[part 10 of 12: packages /Interfaces to /ComponentTypes]
AUTOSAR XML (schema 4-3-0)
package /Interfaces
  1007 x sender receiver interface:
    IF_AB_Deaktivierung_HV
      data DE_AB_Deaktivierung_HV: type=uint8
    IF_Anzeige_SOC
      data DE_Anzeige_SOC: type=uint16
    IF_BJB_10_BZ
      data DE_BJB_10_BZ: type=uint8
    IF_BJB_10_CRC
      data DE_BJB_10_CRC: type=uint8
    IF_BJB_11_BZ
      data DE_BJB_11_BZ: type=uint8
    IF_BJB_11_CRC
      data DE_BJB_11_CRC: type=uint8
    IF_BJB_12_BZ
      data DE_BJB_12_BZ: type=uint8
    IF_BJB_12_CRC
      data DE_BJB_12_CRC: type=uint8
    IF_BJB_13_BZ
      data DE_BJB_13_BZ: type=uint8
    IF_BJB_13_CRC
      data DE_BJB_13_CRC: type=uint8
    IF_BJB_CALID_Index_01
      data DE_BJB_CALID_Index_01: type=uint8
    IF_BJB_CALID_Index_02
      data DE_BJB_CALID_Index_02: type=uint8
    IF_BJB_CALID_Index_03
      data DE_BJB_CALID_Index_03: type=uint8
    IF_BJB_CALID_Index_04
      data DE_BJB_CALID_Index_04: type=uint8
    IF_BJB_CALID_Index_05
      data DE_BJB_CALID_Index_05: type=uint8
    IF_BJB_CALID_Index_06
      data DE_BJB_CALID_Index_06: type=uint8
    IF_BJB_CALID_Index_07
      data DE_BJB_CALID_Index_07: type=uint8
    IF_BJB_CALID_Index_08
      data DE_BJB_CALID_Index_08: type=uint8
    IF_BJB_CALID_Index_09
      data DE_BJB_CALID_Index_09: type=uint8
    IF_BJB_CALID_Index_10
      data DE_BJB_CALID_Index_10: type=uint8
    IF_BJB_CALID_Index_11
      data DE_BJB_CALID_Index_11: type=uint8
    IF_BJB_CALID_Index_12
      data DE_BJB_CALID_Index_12: type=uint8
    IF_BJB_CALID_Index_13
      data DE_BJB_CALID_Index_13: type=uint8
    IF_BJB_CALID_Index_14
      data DE_BJB_CALID_Index_14: type=uint8
    IF_BJB_CALID_Index_15
      data DE_BJB_CALID_Index_15: type=uint8
    IF_BJB_CALID_Index_16
      data DE_BJB_CALID_Index_16: type=uint8
    IF_BJB_CVN_Byte_1
      data DE_BJB_CVN_Byte_1: type=uint8
    IF_BJB_CVN_Byte_2
      data DE_BJB_CVN_Byte_2: type=uint8
    IF_BJB_CVN_Byte_3
      data DE_BJB_CVN_Byte_3: type=uint8
    IF_BJB_CVN_Byte_4
      data DE_BJB_CVN_Byte_4: type=uint8
    IF_BJB_CVN_VLD
      data DE_BJB_CVN_VLD: type=boolean
    IF_BJB_ErrMem_State
      data DE_BJB_ErrMem_State: type=uint8
    IF_BJB_Lebensdauer_Trennelemente
      data DE_BJB_Lebensdauer_Trennelemente: type=uint32
    IF_BJB_Sperrung_Ueberspannung
      data DE_BJB_Sperrung_Ueberspannung: type=uint8
    IF_BJB_Sperrung_Uebertemperatur
      data DE_BJB_Sperrung_Uebertemperatur: type=uint8
    IF_BJB_Sperrung_Unterspannung
      data DE_BJB_Sperrung_Unterspannung: type=uint8
    IF_BJB_Status_HV_Spannungssensorik
      data DE_BJB_Status_HV_Spannungssensorik: type=boolean
    IF_BJB_Status_Trennelemente
      data DE_BJB_Status_Trennelemente: type=uint8
    IF_BJB_Ueberspannungszaehler_CMC01
      data DE_BJB_Ueberspannungszaehler_CMC01: type=uint16
    IF_BJB_Ueberspannungszaehler_CMC02
      data DE_BJB_Ueberspannungszaehler_CMC02: type=uint16
    IF_BJB_Ueberspannungszaehler_CMC03
      data DE_BJB_Ueberspannungszaehler_CMC03: type=uint16
    IF_BJB_Ueberspannungszaehler_CMC04
      data DE_BJB_Ueberspannungszaehler_CMC04: type=uint16
    IF_BJB_Uebertemperaturzaehler_CMC01
      data DE_BJB_Uebertemperaturzaehler_CMC01: type=uint16
    IF_BJB_Uebertemperaturzaehler_CMC02
      data DE_BJB_Uebertemperaturzaehler_CMC02: type=uint16
    IF_BJB_Uebertemperaturzaehler_CMC03
      data DE_BJB_Uebertemperaturzaehler_CMC03: type=uint16
    IF_BJB_Uebertemperaturzaehler_CMC04
      data DE_BJB_Uebertemperaturzaehler_CMC04: type=uint16
    IF_BJB_Unterspannungszaehler_CMC01
      data DE_BJB_Unterspannungszaehler_CMC01: type=uint16
    IF_BJB_Unterspannungszaehler_CMC02
      data DE_BJB_Unterspannungszaehler_CMC02: type=uint16
    IF_BJB_Unterspannungszaehler_CMC03
      data DE_BJB_Unterspannungszaehler_CMC03: type=uint16
    IF_BJB_Unterspannungszaehler_CMC04
      data DE_BJB_Unterspannungszaehler_CMC04: type=uint16
    IF_BMC_Abschaltankuendigung
      data DE_BMC_Abschaltankuendigung: type=uint16
    IF_BMC_AC_Laden
      data DE_BMC_AC_Laden: type=uint8
    IF_BMC_Bank_Notlauf_erlaubt
      data DE_BMC_Bank_Notlauf_erlaubt: type=boolean
    IF_BMC_Bank_parallel_erlaubt
      data DE_BMC_Bank_parallel_erlaubt: type=boolean
    IF_BMC_Bank_seriell_erlaubt
      data DE_BMC_Bank_seriell_erlaubt: type=boolean
    IF_BMC_Bankstatus
      data DE_BMC_Bankstatus: type=uint8
    IF_BMC_Bidi_Energie_Absolut
      data DE_BMC_Bidi_Energie_Absolut: type=uint16
    IF_BMC_Bidi_Freigabe
      data DE_BMC_Bidi_Freigabe: type=uint8
    IF_BMC_Bidi_GenutzteEnergie
      data DE_BMC_Bidi_GenutzteEnergie: type=uint16
    IF_BMC_Bidi_Max_SoC
      data DE_BMC_Bidi_Max_SoC: type=uint8
    IF_BMC_Bidi_Min_SoC
      data DE_BMC_Bidi_Min_SoC: type=uint8
    IF_BMC_Bidi_Veto_Energie
      data DE_BMC_Bidi_Veto_Energie: type=boolean
    IF_BMC_Bidi_Veto_Temp
      data DE_BMC_Bidi_Veto_Temp: type=boolean
    IF_BMC_CMC_Temperatur_001
      data DE_BMC_CMC_Temperatur_001: type=uint8
    IF_BMC_CMC_Temperatur_002
      data DE_BMC_CMC_Temperatur_002: type=uint8
    IF_BMC_CMC_Temperatur_003
      data DE_BMC_CMC_Temperatur_003: type=uint8
    IF_BMC_CMC_Temperatur_004
      data DE_BMC_CMC_Temperatur_004: type=uint8
    IF_BMC_CMC_Temperatur_005
      data DE_BMC_CMC_Temperatur_005: type=uint8
    IF_BMC_CMC_Temperatur_006
      data DE_BMC_CMC_Temperatur_006: type=uint8
    IF_BMC_CMC_Temperatur_007
      data DE_BMC_CMC_Temperatur_007: type=uint8
    IF_BMC_CMC_Temperatur_008
      data DE_BMC_CMC_Temperatur_008: type=uint8
    IF_BMC_CMC_Temperatur_009
      data DE_BMC_CMC_Temperatur_009: type=uint8
    IF_BMC_CMC_Temperatur_010
      data DE_BMC_CMC_Temperatur_010: type=uint8
    IF_BMC_CMC_Temperatur_011
      data DE_BMC_CMC_Temperatur_011: type=uint8
    IF_BMC_CMC_Temperatur_012
      data DE_BMC_CMC_Temperatur_012: type=uint8
    IF_BMC_CMC_Temperatur_013
      data DE_BMC_CMC_Temperatur_013: type=uint8
    IF_BMC_CMC_Temperatur_014
      data DE_BMC_CMC_Temperatur_014: type=uint8
    IF_BMC_CMC_Temperatur_015
      data DE_BMC_CMC_Temperatur_015: type=uint8
    IF_BMC_CMC_Temperatur_016
      data DE_BMC_CMC_Temperatur_016: type=uint8
    IF_BMC_CMC_Temperatur_017
      data DE_BMC_CMC_Temperatur_017: type=uint8
    IF_BMC_CMC_Temperatur_018
      data DE_BMC_CMC_Temperatur_018: type=uint8
    IF_BMC_CMC_Temperatur_019
      data DE_BMC_CMC_Temperatur_019: type=uint8
    IF_BMC_CMC_Temperatur_01_Messzeit
      data DE_BMC_CMC_Temperatur_01_Messzeit: type=uint8
    IF_BMC_CMC_Temperatur_020
      data DE_BMC_CMC_Temperatur_020: type=uint8
    IF_BMC_CMC_Temperatur_021
      data DE_BMC_CMC_Temperatur_021: type=uint8
    IF_BMC_CMC_Temperatur_022
      data DE_BMC_CMC_Temperatur_022: type=uint8
    IF_BMC_CMC_Temperatur_023
      data DE_BMC_CMC_Temperatur_023: type=uint8
    IF_BMC_CMC_Temperatur_024
      data DE_BMC_CMC_Temperatur_024: type=uint8
    IF_BMC_CMC_Temperatur_025
      data DE_BMC_CMC_Temperatur_025: type=uint8
    IF_BMC_CMC_Temperatur_026
      data DE_BMC_CMC_Temperatur_026: type=uint8
    IF_BMC_CMC_Temperatur_027
      data DE_BMC_CMC_Temperatur_027: type=uint8
    IF_BMC_CMC_Temperatur_028
      data DE_BMC_CMC_Temperatur_028: type=uint8
    IF_BMC_CMC_Temperatur_029
      data DE_BMC_CMC_Temperatur_029: type=uint8
    IF_BMC_CMC_Temperatur_02_Messzeit
      data DE_BMC_CMC_Temperatur_02_Messzeit: type=uint8
    IF_BMC_CMC_Temperatur_030
      data DE_BMC_CMC_Temperatur_030: type=uint8
    IF_BMC_CMC_Temperatur_031
      data DE_BMC_CMC_Temperatur_031: type=uint8
    IF_BMC_CMC_Temperatur_032
      data DE_BMC_CMC_Temperatur_032: type=uint8
    IF_BMC_CMC_Temperatur_033
      data DE_BMC_CMC_Temperatur_033: type=uint8
    IF_BMC_CMC_Temperatur_034
      data DE_BMC_CMC_Temperatur_034: type=uint8
    IF_BMC_CMC_Temperatur_035
      data DE_BMC_CMC_Temperatur_035: type=uint8
    IF_BMC_CMC_Temperatur_036
      data DE_BMC_CMC_Temperatur_036: type=uint8
    IF_BMC_CMC_Temperatur_037
      data DE_BMC_CMC_Temperatur_037: type=uint8
    IF_BMC_CMC_Temperatur_038
      data DE_BMC_CMC_Temperatur_038: type=uint8
    IF_BMC_CMC_Temperatur_039
      data DE_BMC_CMC_Temperatur_039: type=uint8
    IF_BMC_CMC_Temperatur_03_Messzeit
      data DE_BMC_CMC_Temperatur_03_Messzeit: type=uint8
    IF_BMC_CMC_Temperatur_040
      data DE_BMC_CMC_Temperatur_040: type=uint8
    IF_BMC_CMC_Temperatur_041
      data DE_BMC_CMC_Temperatur_041: type=uint8
    IF_BMC_CMC_Temperatur_042
      data DE_BMC_CMC_Temperatur_042: type=uint8
    IF_BMC_CMC_Temperatur_043
      data DE_BMC_CMC_Temperatur_043: type=uint8
    IF_BMC_CMC_Temperatur_044
      data DE_BMC_CMC_Temperatur_044: type=uint8
    IF_BMC_CMC_Temperatur_045
      data DE_BMC_CMC_Temperatur_045: type=uint8
    IF_BMC_CMC_Temperatur_046
      data DE_BMC_CMC_Temperatur_046: type=uint8
    IF_BMC_CMC_Temperatur_047
      data DE_BMC_CMC_Temperatur_047: type=uint8
    IF_BMC_CMC_Temperatur_048
      data DE_BMC_CMC_Temperatur_048: type=uint8
    IF_BMC_CMC_Temperatur_049
      data DE_BMC_CMC_Temperatur_049: type=uint8
    IF_BMC_CMC_Temperatur_050
      data DE_BMC_CMC_Temperatur_050: type=uint8
    IF_BMC_CMC_Temperatur_051
      data DE_BMC_CMC_Temperatur_051: type=uint8
    IF_BMC_CMC_Temperatur_052
      data DE_BMC_CMC_Temperatur_052: type=uint8
    IF_BMC_CMC_Temperatur_053
      data DE_BMC_CMC_Temperatur_053: type=uint8
    IF_BMC_CMC_Temperatur_054
      data DE_BMC_CMC_Temperatur_054: type=uint8
    IF_BMC_CMC_Temperatur_055
      data DE_BMC_CMC_Temperatur_055: type=uint8
    IF_BMC_CMC_Temperatur_056
      data DE_BMC_CMC_Temperatur_056: type=uint8
    IF_BMC_CMC_Temperatur_057
      data DE_BMC_CMC_Temperatur_057: type=uint8
    IF_BMC_CMC_Temperatur_058
      data DE_BMC_CMC_Temperatur_058: type=uint8
    IF_BMC_CMC_Temperatur_059
      data DE_BMC_CMC_Temperatur_059: type=uint8
    IF_BMC_CMC_Temperatur_060
      data DE_BMC_CMC_Temperatur_060: type=uint8
    IF_BMC_CMC_Temperatur_061
      data DE_BMC_CMC_Temperatur_061: type=uint8
    IF_BMC_CMC_Temperatur_062
      data DE_BMC_CMC_Temperatur_062: type=uint8
    IF_BMC_CMC_Temperatur_063
      data DE_BMC_CMC_Temperatur_063: type=uint8
    IF_BMC_CMC_Temperatur_064
      data DE_BMC_CMC_Temperatur_064: type=uint8
    IF_BMC_CMC_Temperatur_065
      data DE_BMC_CMC_Temperatur_065: type=uint8
    IF_BMC_CMC_Temperatur_066
      data DE_BMC_CMC_Temperatur_066: type=uint8
    IF_BMC_CMC_Temperatur_067
      data DE_BMC_CMC_Temperatur_067: type=uint8
    IF_BMC_CMC_Temperatur_068
      data DE_BMC_CMC_Temperatur_068: type=uint8
    IF_BMC_CMC_Temperatur_069
      data DE_BMC_CMC_Temperatur_069: type=uint8
    IF_BMC_CMC_Temperatur_070
      data DE_BMC_CMC_Temperatur_070: type=uint8
    IF_BMC_CMC_Temperatur_071
      data DE_BMC_CMC_Temperatur_071: type=uint8
    IF_BMC_CMC_Temperatur_072
      data DE_BMC_CMC_Temperatur_072: type=uint8
    IF_BMC_CMC_Temperatur_073
      data DE_BMC_CMC_Temperatur_073: type=uint8
    IF_BMC_CMC_Temperatur_074
      data DE_BMC_CMC_Temperatur_074: type=uint8
    IF_BMC_CMC_Temperatur_075
      data DE_BMC_CMC_Temperatur_075: type=uint8
    IF_BMC_CMC_Temperatur_076
      data DE_BMC_CMC_Temperatur_076: type=uint8
    IF_BMC_CMC_Temperatur_077
      data DE_BMC_CMC_Temperatur_077: type=uint8
    IF_BMC_CMC_Temperatur_078
      data DE_BMC_CMC_Temperatur_078: type=uint8
    IF_BMC_CMC_Temperatur_079
      data DE_BMC_CMC_Temperatur_079: type=uint8
    IF_BMC_CMC_Temperatur_080
      data DE_BMC_CMC_Temperatur_080: type=uint8
    IF_BMC_CMC_Temperatur_081
      data DE_BMC_CMC_Temperatur_081: type=uint8
    IF_BMC_CMC_Temperatur_082
      data DE_BMC_CMC_Temperatur_082: type=uint8
    IF_BMC_CMC_Temperatur_083
      data DE_BMC_CMC_Temperatur_083: type=uint8
    IF_BMC_CMC_Temperatur_084
      data DE_BMC_CMC_Temperatur_084: type=uint8
    IF_BMC_CMC_Temperatur_085
      data DE_BMC_CMC_Temperatur_085: type=uint8
    IF_BMC_CMC_Temperatur_086
      data DE_BMC_CMC_Temperatur_086: type=uint8
    IF_BMC_CMC_Temperatur_087
      data DE_BMC_CMC_Temperatur_087: type=uint8
    IF_BMC_CMC_Temperatur_088
      data DE_BMC_CMC_Temperatur_088: type=uint8
    IF_BMC_CMC_Temperatur_089
      data DE_BMC_CMC_Temperatur_089: type=uint8
    IF_BMC_CMC_Temperatur_090
      data DE_BMC_CMC_Temperatur_090: type=uint8
    IF_BMC_CMC_Temperatur_091
      data DE_BMC_CMC_Temperatur_091: type=uint8
    IF_BMC_CMC_Temperatur_092
      data DE_BMC_CMC_Temperatur_092: type=uint8
    IF_BMC_CMC_Temperatur_093
      data DE_BMC_CMC_Temperatur_093: type=uint8
    IF_BMC_CMC_Temperatur_094
      data DE_BMC_CMC_Temperatur_094: type=uint8
    IF_BMC_CMC_Temperatur_095
      data DE_BMC_CMC_Temperatur_095: type=uint8
    IF_BMC_CMC_Temperatur_096
      data DE_BMC_CMC_Temperatur_096: type=uint8
    IF_BMC_CMC_Zellspannung_001
      data DE_BMC_CMC_Zellspannung_001: type=uint16
    IF_BMC_CMC_Zellspannung_002
      data DE_BMC_CMC_Zellspannung_002: type=uint16
    IF_BMC_CMC_Zellspannung_003
      data DE_BMC_CMC_Zellspannung_003: type=uint16
    IF_BMC_CMC_Zellspannung_004
      data DE_BMC_CMC_Zellspannung_004: type=uint16
    IF_BMC_CMC_Zellspannung_005
      data DE_BMC_CMC_Zellspannung_005: type=uint16
    IF_BMC_CMC_Zellspannung_006
      data DE_BMC_CMC_Zellspannung_006: type=uint16
    IF_BMC_CMC_Zellspannung_007
      data DE_BMC_CMC_Zellspannung_007: type=uint16
    IF_BMC_CMC_Zellspannung_008
      data DE_BMC_CMC_Zellspannung_008: type=uint16
    IF_BMC_CMC_Zellspannung_009
      data DE_BMC_CMC_Zellspannung_009: type=uint16
    IF_BMC_CMC_Zellspannung_010
      data DE_BMC_CMC_Zellspannung_010: type=uint16
    IF_BMC_CMC_Zellspannung_011
      data DE_BMC_CMC_Zellspannung_011: type=uint16
    IF_BMC_CMC_Zellspannung_012
      data DE_BMC_CMC_Zellspannung_012: type=uint16
    IF_BMC_CMC_Zellspannung_013
      data DE_BMC_CMC_Zellspannung_013: type=uint16
    IF_BMC_CMC_Zellspannung_014
      data DE_BMC_CMC_Zellspannung_014: type=uint16
    IF_BMC_CMC_Zellspannung_015
      data DE_BMC_CMC_Zellspannung_015: type=uint16
    IF_BMC_CMC_Zellspannung_016
      data DE_BMC_CMC_Zellspannung_016: type=uint16
    IF_BMC_CMC_Zellspannung_017
      data DE_BMC_CMC_Zellspannung_017: type=uint16
    IF_BMC_CMC_Zellspannung_018
      data DE_BMC_CMC_Zellspannung_018: type=uint16
    IF_BMC_CMC_Zellspannung_019
      data DE_BMC_CMC_Zellspannung_019: type=uint16
    IF_BMC_CMC_Zellspannung_01_Messzeit
      data DE_BMC_CMC_Zellspannung_01_Messzeit: type=uint8
    IF_BMC_CMC_Zellspannung_020
      data DE_BMC_CMC_Zellspannung_020: type=uint16
    IF_BMC_CMC_Zellspannung_021
      data DE_BMC_CMC_Zellspannung_021: type=uint16
    IF_BMC_CMC_Zellspannung_022
      data DE_BMC_CMC_Zellspannung_022: type=uint16
    IF_BMC_CMC_Zellspannung_023
      data DE_BMC_CMC_Zellspannung_023: type=uint16
    IF_BMC_CMC_Zellspannung_024
      data DE_BMC_CMC_Zellspannung_024: type=uint16
    IF_BMC_CMC_Zellspannung_025
      data DE_BMC_CMC_Zellspannung_025: type=uint16
    IF_BMC_CMC_Zellspannung_026
      data DE_BMC_CMC_Zellspannung_026: type=uint16
    IF_BMC_CMC_Zellspannung_027
      data DE_BMC_CMC_Zellspannung_027: type=uint16
    IF_BMC_CMC_Zellspannung_028
      data DE_BMC_CMC_Zellspannung_028: type=uint16
    IF_BMC_CMC_Zellspannung_029
      data DE_BMC_CMC_Zellspannung_029: type=uint16
    IF_BMC_CMC_Zellspannung_02_Messzeit
      data DE_BMC_CMC_Zellspannung_02_Messzeit: type=uint8
    IF_BMC_CMC_Zellspannung_030
      data DE_BMC_CMC_Zellspannung_030: type=uint16
    IF_BMC_CMC_Zellspannung_031
      data DE_BMC_CMC_Zellspannung_031: type=uint16
    IF_BMC_CMC_Zellspannung_032
      data DE_BMC_CMC_Zellspannung_032: type=uint16
    IF_BMC_CMC_Zellspannung_033
      data DE_BMC_CMC_Zellspannung_033: type=uint16
    IF_BMC_CMC_Zellspannung_034
      data DE_BMC_CMC_Zellspannung_034: type=uint16
    IF_BMC_CMC_Zellspannung_035
      data DE_BMC_CMC_Zellspannung_035: type=uint16
    IF_BMC_CMC_Zellspannung_036
      data DE_BMC_CMC_Zellspannung_036: type=uint16
    IF_BMC_CMC_Zellspannung_037
      data DE_BMC_CMC_Zellspannung_037: type=uint16
    IF_BMC_CMC_Zellspannung_038
      data DE_BMC_CMC_Zellspannung_038: type=uint16
    IF_BMC_CMC_Zellspannung_039
      data DE_BMC_CMC_Zellspannung_039: type=uint16
    IF_BMC_CMC_Zellspannung_03_Messzeit
      data DE_BMC_CMC_Zellspannung_03_Messzeit: type=uint8
    IF_BMC_CMC_Zellspannung_040
      data DE_BMC_CMC_Zellspannung_040: type=uint16
    IF_BMC_CMC_Zellspannung_041
      data DE_BMC_CMC_Zellspannung_041: type=uint16
    IF_BMC_CMC_Zellspannung_042
      data DE_BMC_CMC_Zellspannung_042: type=uint16
    IF_BMC_CMC_Zellspannung_043
      data DE_BMC_CMC_Zellspannung_043: type=uint16
    IF_BMC_CMC_Zellspannung_044
      data DE_BMC_CMC_Zellspannung_044: type=uint16
    IF_BMC_CMC_Zellspannung_045
      data DE_BMC_CMC_Zellspannung_045: type=uint16
    IF_BMC_CMC_Zellspannung_046
      data DE_BMC_CMC_Zellspannung_046: type=uint16
    IF_BMC_CMC_Zellspannung_047
      data DE_BMC_CMC_Zellspannung_047: type=uint16
    IF_BMC_CMC_Zellspannung_048
      data DE_BMC_CMC_Zellspannung_048: type=uint16
    IF_BMC_CMC_Zellspannung_049
      data DE_BMC_CMC_Zellspannung_049: type=uint16
    IF_BMC_CMC_Zellspannung_04_Messzeit
      data DE_BMC_CMC_Zellspannung_04_Messzeit: type=uint8
    IF_BMC_CMC_Zellspannung_050
      data DE_BMC_CMC_Zellspannung_050: type=uint16
    IF_BMC_CMC_Zellspannung_051
      data DE_BMC_CMC_Zellspannung_051: type=uint16
    IF_BMC_CMC_Zellspannung_052
      data DE_BMC_CMC_Zellspannung_052: type=uint16
    IF_BMC_CMC_Zellspannung_053
      data DE_BMC_CMC_Zellspannung_053: type=uint16
    IF_BMC_CMC_Zellspannung_054
      data DE_BMC_CMC_Zellspannung_054: type=uint16
    IF_BMC_CMC_Zellspannung_055
      data DE_BMC_CMC_Zellspannung_055: type=uint16
    IF_BMC_CMC_Zellspannung_056
      data DE_BMC_CMC_Zellspannung_056: type=uint16
    IF_BMC_CMC_Zellspannung_057
      data DE_BMC_CMC_Zellspannung_057: type=uint16
    IF_BMC_CMC_Zellspannung_058
      data DE_BMC_CMC_Zellspannung_058: type=uint16
    IF_BMC_CMC_Zellspannung_059
      data DE_BMC_CMC_Zellspannung_059: type=uint16
    IF_BMC_CMC_Zellspannung_05_Messzeit
      data DE_BMC_CMC_Zellspannung_05_Messzeit: type=uint8
    IF_BMC_CMC_Zellspannung_060
      data DE_BMC_CMC_Zellspannung_060: type=uint16
    IF_BMC_CMC_Zellspannung_061
      data DE_BMC_CMC_Zellspannung_061: type=uint16
    IF_BMC_CMC_Zellspannung_062
      data DE_BMC_CMC_Zellspannung_062: type=uint16
    IF_BMC_CMC_Zellspannung_063
      data DE_BMC_CMC_Zellspannung_063: type=uint16
    IF_BMC_CMC_Zellspannung_064
      data DE_BMC_CMC_Zellspannung_064: type=uint16
    IF_BMC_CMC_Zellspannung_065
      data DE_BMC_CMC_Zellspannung_065: type=uint16
    IF_BMC_CMC_Zellspannung_066
      data DE_BMC_CMC_Zellspannung_066: type=uint16
    IF_BMC_CMC_Zellspannung_067
      data DE_BMC_CMC_Zellspannung_067: type=uint16
    IF_BMC_CMC_Zellspannung_068
      data DE_BMC_CMC_Zellspannung_068: type=uint16
    IF_BMC_CMC_Zellspannung_069
      data DE_BMC_CMC_Zellspannung_069: type=uint16
    IF_BMC_CMC_Zellspannung_070
      data DE_BMC_CMC_Zellspannung_070: type=uint16
    IF_BMC_CMC_Zellspannung_071
      data DE_BMC_CMC_Zellspannung_071: type=uint16
    IF_BMC_CMC_Zellspannung_072
      data DE_BMC_CMC_Zellspannung_072: type=uint16
    IF_BMC_CMC_Zellspannung_073
      data DE_BMC_CMC_Zellspannung_073: type=uint16
    IF_BMC_CMC_Zellspannung_074
      data DE_BMC_CMC_Zellspannung_074: type=uint16
    IF_BMC_CMC_Zellspannung_075
      data DE_BMC_CMC_Zellspannung_075: type=uint16
    IF_BMC_CMC_Zellspannung_076
      data DE_BMC_CMC_Zellspannung_076: type=uint16
    IF_BMC_CMC_Zellspannung_077
      data DE_BMC_CMC_Zellspannung_077: type=uint16
    IF_BMC_CMC_Zellspannung_078
      data DE_BMC_CMC_Zellspannung_078: type=uint16
    IF_BMC_CMC_Zellspannung_079
      data DE_BMC_CMC_Zellspannung_079: type=uint16
    IF_BMC_CMC_Zellspannung_080
      data DE_BMC_CMC_Zellspannung_080: type=uint16
    IF_BMC_CMC_Zellspannung_081
      data DE_BMC_CMC_Zellspannung_081: type=uint16
    IF_BMC_CMC_Zellspannung_082
      data DE_BMC_CMC_Zellspannung_082: type=uint16
    IF_BMC_CMC_Zellspannung_083
      data DE_BMC_CMC_Zellspannung_083: type=uint16
    IF_BMC_CMC_Zellspannung_084
      data DE_BMC_CMC_Zellspannung_084: type=uint16
    IF_BMC_CMC_Zellspannung_085
      data DE_BMC_CMC_Zellspannung_085: type=uint16
    IF_BMC_CMC_Zellspannung_086
      data DE_BMC_CMC_Zellspannung_086: type=uint16
    IF_BMC_CMC_Zellspannung_087
      data DE_BMC_CMC_Zellspannung_087: type=uint16
    IF_BMC_CMC_Zellspannung_088
      data DE_BMC_CMC_Zellspannung_088: type=uint16
    IF_BMC_CMC_Zellspannung_089
      data DE_BMC_CMC_Zellspannung_089: type=uint16
    IF_BMC_CMC_Zellspannung_090
      data DE_BMC_CMC_Zellspannung_090: type=uint16
    IF_BMC_CMC_Zellspannung_091
      data DE_BMC_CMC_Zellspannung_091: type=uint16
    IF_BMC_CMC_Zellspannung_092
      data DE_BMC_CMC_Zellspannung_092: type=uint16
    IF_BMC_CMC_Zellspannung_093
      data DE_BMC_CMC_Zellspannung_093: type=uint16
    IF_BMC_CMC_Zellspannung_094
      data DE_BMC_CMC_Zellspannung_094: type=uint16
    IF_BMC_CMC_Zellspannung_095
      data DE_BMC_CMC_Zellspannung_095: type=uint16
    IF_BMC_CMC_Zellspannung_096
      data DE_BMC_CMC_Zellspannung_096: type=uint16
    IF_BMC_CMC_Zellspannung_097
      data DE_BMC_CMC_Zellspannung_097: type=uint16
    IF_BMC_CMC_Zellspannung_098
      data DE_BMC_CMC_Zellspannung_098: type=uint16
    IF_BMC_CMC_Zellspannung_099
      data DE_BMC_CMC_Zellspannung_099: type=uint16
    IF_BMC_CMC_Zellspannung_100
      data DE_BMC_CMC_Zellspannung_100: type=uint16
    IF_BMC_CMC_Zellspannung_101
      data DE_BMC_CMC_Zellspannung_101: type=uint16
    IF_BMC_CMC_Zellspannung_102
      data DE_BMC_CMC_Zellspannung_102: type=uint16
    IF_BMC_CMC_Zellspannung_103
      data DE_BMC_CMC_Zellspannung_103: type=uint16
    IF_BMC_CMC_Zellspannung_104
      data DE_BMC_CMC_Zellspannung_104: type=uint16
    IF_BMC_CMC_Zellspannung_105
      data DE_BMC_CMC_Zellspannung_105: type=uint16
    IF_BMC_CMC_Zellspannung_106
      data DE_BMC_CMC_Zellspannung_106: type=uint16
    IF_BMC_CMC_Zellspannung_107
      data DE_BMC_CMC_Zellspannung_107: type=uint16
    IF_BMC_CMC_Zellspannung_108
      data DE_BMC_CMC_Zellspannung_108: type=uint16
    IF_BMC_CMC_Zellspannung_109
      data DE_BMC_CMC_Zellspannung_109: type=uint16
    IF_BMC_CMC_Zellspannung_110
      data DE_BMC_CMC_Zellspannung_110: type=uint16
    IF_BMC_CMC_Zellspannung_111
      data DE_BMC_CMC_Zellspannung_111: type=uint16
    IF_BMC_CMC_Zellspannung_112
      data DE_BMC_CMC_Zellspannung_112: type=uint16
    IF_BMC_CMC_Zellspannung_113
      data DE_BMC_CMC_Zellspannung_113: type=uint16
    IF_BMC_CMC_Zellspannung_114
      data DE_BMC_CMC_Zellspannung_114: type=uint16
    IF_BMC_CMC_Zellspannung_115
      data DE_BMC_CMC_Zellspannung_115: type=uint16
    IF_BMC_CMC_Zellspannung_116
      data DE_BMC_CMC_Zellspannung_116: type=uint16
    IF_BMC_CMC_Zellspannung_117
      data DE_BMC_CMC_Zellspannung_117: type=uint16
    IF_BMC_CMC_Zellspannung_118
      data DE_BMC_CMC_Zellspannung_118: type=uint16
    IF_BMC_CMC_Zellspannung_119
      data DE_BMC_CMC_Zellspannung_119: type=uint16
    IF_BMC_CMC_Zellspannung_120
      data DE_BMC_CMC_Zellspannung_120: type=uint16
    IF_BMC_CMC_Zellspannung_121
      data DE_BMC_CMC_Zellspannung_121: type=uint16
    IF_BMC_CMC_Zellspannung_122
      data DE_BMC_CMC_Zellspannung_122: type=uint16
    IF_BMC_CMC_Zellspannung_123
      data DE_BMC_CMC_Zellspannung_123: type=uint16
    IF_BMC_CMC_Zellspannung_124
      data DE_BMC_CMC_Zellspannung_124: type=uint16
    IF_BMC_CMC_Zellspannung_125
      data DE_BMC_CMC_Zellspannung_125: type=uint16
    IF_BMC_CMC_Zellspannung_126
      data DE_BMC_CMC_Zellspannung_126: type=uint16
    IF_BMC_CMC_Zellspannung_127
      data DE_BMC_CMC_Zellspannung_127: type=uint16
    IF_BMC_CMC_Zellspannung_128
      data DE_BMC_CMC_Zellspannung_128: type=uint16
    IF_BMC_CMC_Zellspannung_129
      data DE_BMC_CMC_Zellspannung_129: type=uint16
    IF_BMC_CMC_Zellspannung_130
      data DE_BMC_CMC_Zellspannung_130: type=uint16
    IF_BMC_CMC_Zellspannung_131
      data DE_BMC_CMC_Zellspannung_131: type=uint16
    IF_BMC_CMC_Zellspannung_132
      data DE_BMC_CMC_Zellspannung_132: type=uint16
    IF_BMC_CMC_Zellspannung_133
      data DE_BMC_CMC_Zellspannung_133: type=uint16
    IF_BMC_CMC_Zellspannung_134
      data DE_BMC_CMC_Zellspannung_134: type=uint16
    IF_BMC_CMC_Zellspannung_135
      data DE_BMC_CMC_Zellspannung_135: type=uint16
    IF_BMC_CMC_Zellspannung_136
      data DE_BMC_CMC_Zellspannung_136: type=uint16
    IF_BMC_CMC_Zellspannung_137
      data DE_BMC_CMC_Zellspannung_137: type=uint16
    IF_BMC_CMC_Zellspannung_138
      data DE_BMC_CMC_Zellspannung_138: type=uint16
    IF_BMC_CMC_Zellspannung_139
      data DE_BMC_CMC_Zellspannung_139: type=uint16
    IF_BMC_CMC_Zellspannung_140
      data DE_BMC_CMC_Zellspannung_140: type=uint16
    IF_BMC_CMC_Zellspannung_141
      data DE_BMC_CMC_Zellspannung_141: type=uint16
    IF_BMC_CMC_Zellspannung_142
      data DE_BMC_CMC_Zellspannung_142: type=uint16
    IF_BMC_CMC_Zellspannung_143
      data DE_BMC_CMC_Zellspannung_143: type=uint16
    IF_BMC_CMC_Zellspannung_144
      data DE_BMC_CMC_Zellspannung_144: type=uint16
    IF_BMC_CMC_Zellspannung_145
      data DE_BMC_CMC_Zellspannung_145: type=uint16
    IF_BMC_CMC_Zellspannung_146
      data DE_BMC_CMC_Zellspannung_146: type=uint16
    IF_BMC_CMC_Zellspannung_147
      data DE_BMC_CMC_Zellspannung_147: type=uint16
    IF_BMC_CMC_Zellspannung_148
      data DE_BMC_CMC_Zellspannung_148: type=uint16
    IF_BMC_CMC_Zellspannung_149
      data DE_BMC_CMC_Zellspannung_149: type=uint16
    IF_BMC_CMC_Zellspannung_150
      data DE_BMC_CMC_Zellspannung_150: type=uint16
    IF_BMC_CMC_Zellspannung_151
      data DE_BMC_CMC_Zellspannung_151: type=uint16
    IF_BMC_CMC_Zellspannung_152
      data DE_BMC_CMC_Zellspannung_152: type=uint16
    IF_BMC_CMC_Zellspannung_153
      data DE_BMC_CMC_Zellspannung_153: type=uint16
    IF_BMC_CMC_Zellspannung_154
      data DE_BMC_CMC_Zellspannung_154: type=uint16
    IF_BMC_CMC_Zellspannung_155
      data DE_BMC_CMC_Zellspannung_155: type=uint16
    IF_BMC_CMC_Zellspannung_156
      data DE_BMC_CMC_Zellspannung_156: type=uint16
    IF_BMC_CMC_Zellspannung_157
      data DE_BMC_CMC_Zellspannung_157: type=uint16
    IF_BMC_CMC_Zellspannung_158
      data DE_BMC_CMC_Zellspannung_158: type=uint16
    IF_BMC_CMC_Zellspannung_159
      data DE_BMC_CMC_Zellspannung_159: type=uint16
    IF_BMC_CMC_Zellspannung_160
      data DE_BMC_CMC_Zellspannung_160: type=uint16
    IF_BMC_CMC_Zellspannung_161
      data DE_BMC_CMC_Zellspannung_161: type=uint16
    IF_BMC_CMC_Zellspannung_162
      data DE_BMC_CMC_Zellspannung_162: type=uint16
    IF_BMC_CMC_Zellspannung_163
      data DE_BMC_CMC_Zellspannung_163: type=uint16
    IF_BMC_CMC_Zellspannung_164
      data DE_BMC_CMC_Zellspannung_164: type=uint16
    IF_BMC_CMC_Zellspannung_165
      data DE_BMC_CMC_Zellspannung_165: type=uint16
    IF_BMC_CMC_Zellspannung_166
      data DE_BMC_CMC_Zellspannung_166: type=uint16
    IF_BMC_CMC_Zellspannung_167
      data DE_BMC_CMC_Zellspannung_167: type=uint16
    IF_BMC_CMC_Zellspannung_168
      data DE_BMC_CMC_Zellspannung_168: type=uint16
    IF_BMC_CMC_Zellspannung_169
      data DE_BMC_CMC_Zellspannung_169: type=uint16
    IF_BMC_CMC_Zellspannung_170
      data DE_BMC_CMC_Zellspannung_170: type=uint16
    IF_BMC_CMC_Zellspannung_171
      data DE_BMC_CMC_Zellspannung_171: type=uint16
    IF_BMC_CMC_Zellspannung_172
      data DE_BMC_CMC_Zellspannung_172: type=uint16
    IF_BMC_CMC_Zellspannung_173
      data DE_BMC_CMC_Zellspannung_173: type=uint16
    IF_BMC_CMC_Zellspannung_174
      data DE_BMC_CMC_Zellspannung_174: type=uint16
    IF_BMC_CMC_Zellspannung_175
      data DE_BMC_CMC_Zellspannung_175: type=uint16
    IF_BMC_CMC_Zellspannung_176
      data DE_BMC_CMC_Zellspannung_176: type=uint16
    IF_BMC_CMC_Zellspannung_177
      data DE_BMC_CMC_Zellspannung_177: type=uint16
    IF_BMC_CMC_Zellspannung_178
      data DE_BMC_CMC_Zellspannung_178: type=uint16
    IF_BMC_CMC_Zellspannung_179
      data DE_BMC_CMC_Zellspannung_179: type=uint16
    IF_BMC_CMC_Zellspannung_180
      data DE_BMC_CMC_Zellspannung_180: type=uint16
    IF_BMC_CMC_Zellspannung_181
      data DE_BMC_CMC_Zellspannung_181: type=uint16
    IF_BMC_CMC_Zellspannung_182
      data DE_BMC_CMC_Zellspannung_182: type=uint16
    IF_BMC_CMC_Zellspannung_183
      data DE_BMC_CMC_Zellspannung_183: type=uint16
    IF_BMC_CMC_Zellspannung_184
      data DE_BMC_CMC_Zellspannung_184: type=uint16
    IF_BMC_CMC_Zellspannung_185
      data DE_BMC_CMC_Zellspannung_185: type=uint16
    IF_BMC_CMC_Zellspannung_186
      data DE_BMC_CMC_Zellspannung_186: type=uint16
    IF_BMC_CMC_Zellspannung_187
      data DE_BMC_CMC_Zellspannung_187: type=uint16
    IF_BMC_CMC_Zellspannung_188
      data DE_BMC_CMC_Zellspannung_188: type=uint16
    IF_BMC_CMC_Zellspannung_189
      data DE_BMC_CMC_Zellspannung_189: type=uint16
    IF_BMC_CMC_Zellspannung_190
      data DE_BMC_CMC_Zellspannung_190: type=uint16
    IF_BMC_CMC_Zellspannung_191
      data DE_BMC_CMC_Zellspannung_191: type=uint16
    IF_BMC_CMC_Zellspannung_192
      data DE_BMC_CMC_Zellspannung_192: type=uint16
    IF_BMC_Datenuebernahme_Anf
      data DE_BMC_Datenuebernahme_Anf: type=boolean
    IF_BMC_Dauer_Entladeleistung
      data DE_BMC_Dauer_Entladeleistung: type=uint16
    IF_BMC_Dauer_Entladeleistung_02
      data DE_BMC_Dauer_Entladeleistung_02: type=uint16
    IF_BMC_Dauer_Ladeleistung
      data DE_BMC_Dauer_Ladeleistung: type=uint16
    IF_BMC_Dauer_Ladeleistung_02
      data DE_BMC_Dauer_Ladeleistung_02: type=uint16
    IF_BMC_DC_Laden
      data DE_BMC_DC_Laden: type=uint8
    IF_BMC_Dev_Freigabe
      data DE_BMC_Dev_Freigabe: type=boolean
    IF_BMC_Energie_Entladen
      data DE_BMC_Energie_Entladen: type=uint16
    IF_BMC_Energie_Laden
      data DE_BMC_Energie_Laden: type=uint16
    IF_BMC_Energie_Sockel_SoC
      data DE_BMC_Energie_Sockel_SoC: type=uint16
    IF_BMC_Energieinhalt
      data DE_BMC_Energieinhalt: type=uint16
    IF_BMC_EnergieVorhalt
      data DE_BMC_EnergieVorhalt: type=uint16
    IF_BMC_ExtLadeleistung
      data DE_BMC_ExtLadeleistung: type=uint16
    IF_BMC_Fehler_Leistungsred
      data DE_BMC_Fehler_Leistungsred: type=boolean
    IF_BMC_Fehler_Warnung
      data DE_BMC_Fehler_Warnung: type=uint8
    IF_BMC_Flash_Freigabe
      data DE_BMC_Flash_Freigabe: type=boolean
    IF_BMC_HV_01_BZ
      data DE_BMC_HV_01_BZ: type=uint8
    IF_BMC_HV_01_CRC
      data DE_BMC_HV_01_CRC: type=uint8
    IF_BMC_HV_02_BZ
      data DE_BMC_HV_02_BZ: type=uint8
    IF_BMC_HV_02_CRC
      data DE_BMC_HV_02_CRC: type=uint8
    IF_BMC_HV_04_BZ
      data DE_BMC_HV_04_BZ: type=uint8
    IF_BMC_HV_04_CRC
      data DE_BMC_HV_04_CRC: type=uint8
    IF_BMC_HV_10_BZ
      data DE_BMC_HV_10_BZ: type=uint8
    IF_BMC_HV_10_CRC
      data DE_BMC_HV_10_CRC: type=uint8
    IF_BMC_HV_11_BZ
      data DE_BMC_HV_11_BZ: type=uint8
    IF_BMC_HV_11_CRC
      data DE_BMC_HV_11_CRC: type=uint8
    IF_BMC_HV_12_BZ
      data DE_BMC_HV_12_BZ: type=uint8
    IF_BMC_HV_12_CRC
      data DE_BMC_HV_12_CRC: type=uint8
    IF_BMC_HV_13_BZ
      data DE_BMC_HV_13_BZ: type=uint8
    IF_BMC_HV_13_CRC
      data DE_BMC_HV_13_CRC: type=uint8
    IF_BMC_HVK_EoHVL_Status
      data DE_BMC_HVK_EoHVL_Status: type=uint8
    IF_BMC_HVK_Fehler_HVIL
      data DE_BMC_HVK_Fehler_HVIL: type=uint8
    IF_BMC_HVK_Fehler_Intern
      data DE_BMC_HVK_Fehler_Intern: type=uint8
    IF_BMC_HVK_Fehler_SD
      data DE_BMC_HVK_Fehler_SD: type=uint8
    IF_BMC_Iso_Mode_Anf
      data DE_BMC_Iso_Mode_Anf: type=uint8
    IF_BMC_IstTemperaturMax_Modul_ID
      data DE_BMC_IstTemperaturMax_Modul_ID: type=uint8
    IF_BMC_IstTemperaturMax_Sensor_ID
      data DE_BMC_IstTemperaturMax_Sensor_ID: type=uint8
    IF_BMC_IstTemperaturMin_Modul_ID
      data DE_BMC_IstTemperaturMin_Modul_ID: type=uint8
    IF_BMC_IstTemperaturMin_Sensor_ID
      data DE_BMC_IstTemperaturMin_Sensor_ID: type=uint8
    IF_BMC_IstZellspannungMax
      data DE_BMC_IstZellspannungMax: type=uint16
    IF_BMC_IstZellSpannungMax_Modul_ID
      data DE_BMC_IstZellSpannungMax_Modul_ID: type=uint8
    IF_BMC_IstZellSpannungMax_Zell_ID
      data DE_BMC_IstZellSpannungMax_Zell_ID: type=uint8
    IF_BMC_IstZellspannungMin
      data DE_BMC_IstZellspannungMin: type=uint16
    IF_BMC_IstZellSpannungMin_Modul_ID
      data DE_BMC_IstZellSpannungMin_Modul_ID: type=uint8
    IF_BMC_IstZellSpannungMin_Zell_ID
      data DE_BMC_IstZellSpannungMin_Zell_ID: type=uint8
    IF_BMC_IWU_Status
      data DE_BMC_IWU_Status: type=uint8
    IF_BMC_IWU_Wert_neg
      data DE_BMC_IWU_Wert_neg: type=uint16
    IF_BMC_IWU_Wert_pos
      data DE_BMC_IWU_Wert_pos: type=uint16
    IF_BMC_Konditionierung_Anf
      data DE_BMC_Konditionierung_Anf: type=boolean
    IF_BMC_KundenWarnung
      data DE_BMC_KundenWarnung: type=uint8
    IF_BMC_Lebensdauer_Trennelemente
      data DE_BMC_Lebensdauer_Trennelemente: type=uint32
    IF_BMC_Leerlaufspannung
      data DE_BMC_Leerlaufspannung: type=uint16
    IF_BMC_Max_Entladeleistung
      data DE_BMC_Max_Entladeleistung: type=uint16
    IF_BMC_Max_Entladeleistung_02
      data DE_BMC_Max_Entladeleistung_02: type=uint16
    IF_BMC_Max_Entladestrom
      data DE_BMC_Max_Entladestrom: type=uint16
    IF_BMC_Max_Entladestrom_02
      data DE_BMC_Max_Entladestrom_02: type=uint16
    IF_BMC_Max_Ladeleistung
      data DE_BMC_Max_Ladeleistung: type=uint16
    IF_BMC_Max_Ladeleistung_02
      data DE_BMC_Max_Ladeleistung_02: type=uint16
    IF_BMC_Max_Ladestrom
      data DE_BMC_Max_Ladestrom: type=uint16
    IF_BMC_Max_Ladestrom_02
      data DE_BMC_Max_Ladestrom_02: type=uint16
    IF_BMC_Max_Spannung
      data DE_BMC_Max_Spannung: type=uint16
    IF_BMC_MaxEnergieinhalt
      data DE_BMC_MaxEnergieinhalt: type=uint16
    IF_BMC_Min_Spannung
      data DE_BMC_Min_Spannung: type=uint16
    IF_BMC_MinDyn_Entladespannung
      data DE_BMC_MinDyn_Entladespannung: type=uint16
    IF_BMC_MinDyn_Ladespannung
      data DE_BMC_MinDyn_Ladespannung: type=uint16
    IF_BMC_MMTR_Status
      data DE_BMC_MMTR_Status: type=uint8
    IF_BMC_Modus
      data DE_BMC_Modus: type=uint8
    IF_BMC_NutzbareKapazitaet
      data DE_BMC_NutzbareKapazitaet: type=uint16
    IF_BMC_NutzbarerSOC
      data DE_BMC_NutzbarerSOC: type=uint16
    IF_BMC_Pack_SN_01
      data DE_BMC_Pack_SN_01: type=uint8
    IF_BMC_Pack_SN_02
      data DE_BMC_Pack_SN_02: type=uint8
    IF_BMC_Pack_SN_03
      data DE_BMC_Pack_SN_03: type=uint8
    IF_BMC_Pack_SN_04
      data DE_BMC_Pack_SN_04: type=uint8
    IF_BMC_Pack_SN_05
      data DE_BMC_Pack_SN_05: type=uint8
    IF_BMC_Pack_SN_06
      data DE_BMC_Pack_SN_06: type=uint8
    IF_BMC_Pack_SN_07
      data DE_BMC_Pack_SN_07: type=uint8
    IF_BMC_Pack_SN_08
      data DE_BMC_Pack_SN_08: type=uint8
    IF_BMC_Pack_SN_09
      data DE_BMC_Pack_SN_09: type=uint8
    IF_BMC_Pack_SN_10
      data DE_BMC_Pack_SN_10: type=uint8
    IF_BMC_Pack_SN_11
      data DE_BMC_Pack_SN_11: type=uint8
    IF_BMC_Pack_SN_12
      data DE_BMC_Pack_SN_12: type=uint8
    IF_BMC_Pack_SN_13
      data DE_BMC_Pack_SN_13: type=uint8
    IF_BMC_Pack_SN_14
      data DE_BMC_Pack_SN_14: type=uint8
    IF_BMC_Pack_SN_15
      data DE_BMC_Pack_SN_15: type=uint8
    IF_BMC_Pack_SN_16
      data DE_BMC_Pack_SN_16: type=uint8
    IF_BMC_Pack_SN_17
      data DE_BMC_Pack_SN_17: type=uint8
    IF_BMC_Pack_SN_18
      data DE_BMC_Pack_SN_18: type=uint8
    IF_BMC_Pack_SN_19
      data DE_BMC_Pack_SN_19: type=uint8
    IF_BMC_Pack_SN_20
      data DE_BMC_Pack_SN_20: type=uint8
    IF_BMC_Pack_SN_21
      data DE_BMC_Pack_SN_21: type=uint8
    IF_BMC_Pack_SN_22
      data DE_BMC_Pack_SN_22: type=uint8
    IF_BMC_Pack_SN_23
      data DE_BMC_Pack_SN_23: type=uint8
    IF_BMC_Pack_SN_24
      data DE_BMC_Pack_SN_24: type=uint8
    IF_BMC_Pack_SN_25
      data DE_BMC_Pack_SN_25: type=uint8
    IF_BMC_Pack_SN_26
      data DE_BMC_Pack_SN_26: type=uint8
    IF_BMC_PCM_VTD_Freeze_Req
      data DE_BMC_PCM_VTD_Freeze_Req: type=uint8
    IF_BMC_PCM_VTD_LifeTimeReset_Req
      data DE_BMC_PCM_VTD_LifeTimeReset_Req: type=uint8
    IF_BMC_PCM_VTD_LifeTimeReset_Resp
      data DE_BMC_PCM_VTD_LifeTimeReset_Resp: type=uint8
    IF_BMC_PCM_VTD_RecentReset_Req
      data DE_BMC_PCM_VTD_RecentReset_Req: type=uint8
    IF_BMC_PerfInd_Entladen
      data DE_BMC_PerfInd_Entladen: type=uint16
    IF_BMC_PerfInd_Laden
      data DE_BMC_PerfInd_Laden: type=uint16
    IF_BMC_PredLeistung_StuetzungNV
      data DE_BMC_PredLeistung_StuetzungNV: type=uint16
    IF_BMC_Range_Indikator
      data DE_BMC_Range_Indikator: type=uint16
    IF_BMC_Rekuperation
      data DE_BMC_Rekuperation: type=uint16
    IF_BMC_Rekuperation_Ueberlauf
      data DE_BMC_Rekuperation_Ueberlauf: type=boolean
    IF_BMC_RtmWarnBattUnautorisiert
      data DE_BMC_RtmWarnBattUnautorisiert: type=uint8
    IF_BMC_RtmWarnPackKommunikation
      data DE_BMC_RtmWarnPackKommunikation: type=uint8
    IF_BMC_RtmWarnPackUeberladen
      data DE_BMC_RtmWarnPackUeberladen: type=uint8
    IF_BMC_RtmWarnSocHoch
      data DE_BMC_RtmWarnSocHoch: type=uint8
    IF_BMC_RtmWarnSocNiedrig
      data DE_BMC_RtmWarnSocNiedrig: type=uint8
    IF_BMC_RtmWarnSocSprung
      data DE_BMC_RtmWarnSocSprung: type=uint8
    IF_BMC_RtmWarnTZelleDiff
      data DE_BMC_RtmWarnTZelleDiff: type=uint8
    IF_BMC_RtmWarnTZelleMax
      data DE_BMC_RtmWarnTZelleMax: type=uint8
    IF_BMC_RtmWarnTZelleMin
      data DE_BMC_RtmWarnTZelleMin: type=uint8
    IF_BMC_RtmWarnUeberstrom
      data DE_BMC_RtmWarnUeberstrom: type=uint8
    IF_BMC_RtmWarnUPackMax
      data DE_BMC_RtmWarnUPackMax: type=uint8
    IF_BMC_RtmWarnUPackMin
      data DE_BMC_RtmWarnUPackMin: type=uint8
    IF_BMC_RtmWarnUZelleMax
      data DE_BMC_RtmWarnUZelleMax: type=uint8
    IF_BMC_RtmWarnUZelleMin
      data DE_BMC_RtmWarnUZelleMin: type=uint8
    IF_BMC_RtmWarnZelleZustand
      data DE_BMC_RtmWarnZelleZustand: type=uint8
    IF_BMC_RuecklaufTemperatur
      data DE_BMC_RuecklaufTemperatur: type=uint16
    IF_BMC_Spannung
      data DE_BMC_Spannung: type=uint16
    IF_BMC_Spannung_DC_Ladesaeule
      data DE_BMC_Spannung_DC_Ladesaeule: type=uint16
    IF_BMC_Spannung_Messzeit
      data DE_BMC_Spannung_Messzeit: type=uint8
    IF_BMC_Spannung_ZwischenKreis
      data DE_BMC_Spannung_ZwischenKreis: type=uint16
    IF_BMC_Spannung_ZwischenKreis_2
      data DE_BMC_Spannung_ZwischenKreis_2: type=uint16
    IF_BMC_Sperrung_Ueberspannung
      data DE_BMC_Sperrung_Ueberspannung: type=uint8
    IF_BMC_Sperrung_Uebertemperatur
      data DE_BMC_Sperrung_Uebertemperatur: type=uint8
    IF_BMC_Sperrung_Unterspannung
      data DE_BMC_Sperrung_Unterspannung: type=uint8
    IF_BMC_Status_DCLS
      data DE_BMC_Status_DCLS: type=uint8
    IF_BMC_Status_HV_Spannungssensorik
      data DE_BMC_Status_HV_Spannungssensorik: type=boolean
    IF_BMC_Status_Spgfreiheit
      data DE_BMC_Status_Spgfreiheit: type=uint8
    IF_BMC_Status_Trennelemente
      data DE_BMC_Status_Trennelemente: type=uint8
    IF_BMC_Strom
      data DE_BMC_Strom: type=uint16
    IF_BMC_Strom_02
      data DE_BMC_Strom_02: type=uint32
    IF_BMC_Strom_Messzeit
      data DE_BMC_Strom_Messzeit: type=uint8
    IF_BMC_TechnischerSOC
      data DE_BMC_TechnischerSOC: type=uint16
    IF_BMC_Temperatur
      data DE_BMC_Temperatur: type=uint16
    IF_BMC_Temperatur_hoechste
      data DE_BMC_Temperatur_hoechste: type=uint16
    IF_BMC_Temperatur_niedrigste
      data DE_BMC_Temperatur_niedrigste: type=uint16
    IF_BMC_ThermAuslastung
      data DE_BMC_ThermAuslastung: type=uint8
    IF_BMC_ThermSpreizung
      data DE_BMC_ThermSpreizung: type=uint8
    IF_BMC_UBE_Indik_last_update_km
      data DE_BMC_UBE_Indik_last_update_km: type=uint32
    IF_BMC_UBE_Indikator
      data DE_BMC_UBE_Indikator: type=uint16
    IF_BMC_Ueberspannungszaehler_CMC01
      data DE_BMC_Ueberspannungszaehler_CMC01: type=uint16
    IF_BMC_Ueberspannungszaehler_CMC02
      data DE_BMC_Ueberspannungszaehler_CMC02: type=uint16
    IF_BMC_Ueberspannungszaehler_CMC03
      data DE_BMC_Ueberspannungszaehler_CMC03: type=uint16
    IF_BMC_Ueberspannungszaehler_CMC04
      data DE_BMC_Ueberspannungszaehler_CMC04: type=uint16
    IF_BMC_Uebertemperaturzaehler_CMC01
      data DE_BMC_Uebertemperaturzaehler_CMC01: type=uint16
    IF_BMC_Uebertemperaturzaehler_CMC02
      data DE_BMC_Uebertemperaturzaehler_CMC02: type=uint16
    IF_BMC_Uebertemperaturzaehler_CMC03
      data DE_BMC_Uebertemperaturzaehler_CMC03: type=uint16
    IF_BMC_Uebertemperaturzaehler_CMC04
      data DE_BMC_Uebertemperaturzaehler_CMC04: type=uint16
    IF_BMC_UI1_Spannung1_Schalt_Anf
      data DE_BMC_UI1_Spannung1_Schalt_Anf: type=boolean
    IF_BMC_UI1_Spannung2_Schalt_Anf
      data DE_BMC_UI1_Spannung2_Schalt_Anf: type=boolean
    IF_BMC_UI2_Spannung1_Schalt_Anf
      data DE_BMC_UI2_Spannung1_Schalt_Anf: type=boolean
    IF_BMC_UI2_Spannung2_Schalt_Anf
      data DE_BMC_UI2_Spannung2_Schalt_Anf: type=boolean
    IF_BMC_Unterboden_Warnung
      data DE_BMC_Unterboden_Warnung: type=uint8
    IF_BMC_Unterspannungszaehler_CMC01
      data DE_BMC_Unterspannungszaehler_CMC01: type=uint16
    IF_BMC_Unterspannungszaehler_CMC02
      data DE_BMC_Unterspannungszaehler_CMC02: type=uint16
    IF_BMC_Unterspannungszaehler_CMC03
      data DE_BMC_Unterspannungszaehler_CMC03: type=uint16
    IF_BMC_Unterspannungszaehler_CMC04
      data DE_BMC_Unterspannungszaehler_CMC04: type=uint16
    IF_BMC_Verbauinfo_ACSchuetz
      data DE_BMC_Verbauinfo_ACSchuetz: type=uint8
    IF_BMC_Verbauinfo_Bank
      data DE_BMC_Verbauinfo_Bank: type=uint8
    IF_BMC_Verbrauch
      data DE_BMC_Verbrauch: type=uint16
    IF_BMC_Verbrauch_Ueberlauf
      data DE_BMC_Verbrauch_Ueberlauf: type=boolean
    IF_BMC_VerlustEnergie
      data DE_BMC_VerlustEnergie: type=uint16
    IF_BMC_Vorlade_Zielspannung
      data DE_BMC_Vorlade_Zielspannung: type=uint16
    IF_BMC_VorlaufTemperatur
      data DE_BMC_VorlaufTemperatur: type=uint16
    IF_BMC_ZellTemp_virtuell_max
      data DE_BMC_ZellTemp_virtuell_max: type=uint16
    IF_BMC_ZellTemp_virtuell_min
      data DE_BMC_ZellTemp_virtuell_min: type=uint16
    IF_CHA_ReqPrgBms
      data DE_CHA_ReqPrgBms: type=uint8
    IF_DC_IstLeistung_HV
      data DE_DC_IstLeistung_HV: type=uint16
    IF_DCDC_NV_CALID_Index_01
      data DE_DCDC_NV_CALID_Index_01: type=uint8
    IF_DCDC_NV_CALID_Index_02
      data DE_DCDC_NV_CALID_Index_02: type=uint8
    IF_DCDC_NV_CALID_Index_03
      data DE_DCDC_NV_CALID_Index_03: type=uint8
    IF_DCDC_NV_CALID_Index_04
      data DE_DCDC_NV_CALID_Index_04: type=uint8
    IF_DCDC_NV_CALID_Index_05
      data DE_DCDC_NV_CALID_Index_05: type=uint8
    IF_DCDC_NV_CALID_Index_06
      data DE_DCDC_NV_CALID_Index_06: type=uint8
    IF_DCDC_NV_CALID_Index_07
      data DE_DCDC_NV_CALID_Index_07: type=uint8
    IF_DCDC_NV_CALID_Index_08
      data DE_DCDC_NV_CALID_Index_08: type=uint8
    IF_DCDC_NV_CALID_Index_09
      data DE_DCDC_NV_CALID_Index_09: type=uint8
    IF_DCDC_NV_CALID_Index_10
      data DE_DCDC_NV_CALID_Index_10: type=uint8
    IF_DCDC_NV_CALID_Index_11
      data DE_DCDC_NV_CALID_Index_11: type=uint8
    IF_DCDC_NV_CALID_Index_12
      data DE_DCDC_NV_CALID_Index_12: type=uint8
    IF_DCDC_NV_CALID_Index_13
      data DE_DCDC_NV_CALID_Index_13: type=uint8
    IF_DCDC_NV_CALID_Index_14
      data DE_DCDC_NV_CALID_Index_14: type=uint8
    IF_DCDC_NV_CALID_Index_15
      data DE_DCDC_NV_CALID_Index_15: type=uint8
    IF_DCDC_NV_CALID_Index_16
      data DE_DCDC_NV_CALID_Index_16: type=uint8
    IF_DCDC_NV_CVN_Byte_1
      data DE_DCDC_NV_CVN_Byte_1: type=uint8
    IF_DCDC_NV_CVN_Byte_2
      data DE_DCDC_NV_CVN_Byte_2: type=uint8
    IF_DCDC_NV_CVN_Byte_3
      data DE_DCDC_NV_CVN_Byte_3: type=uint8
    IF_DCDC_NV_CVN_Byte_4
      data DE_DCDC_NV_CVN_Byte_4: type=uint8
    IF_DCDC_NV_CVN_VLD
      data DE_DCDC_NV_CVN_VLD: type=boolean
    IF_DCDC_NV_Komponentenfehler_01
      data DE_DCDC_NV_Komponentenfehler_01: type=uint8
    IF_DCDC_NV_Komponentenfehler_02
      data DE_DCDC_NV_Komponentenfehler_02: type=uint8
    IF_DCDC_NV_Komponentenfehler_03
      data DE_DCDC_NV_Komponentenfehler_03: type=uint8
    IF_DCDC_NV_Komponentenfehler_04
      data DE_DCDC_NV_Komponentenfehler_04: type=uint8
    IF_DCDC_NV_Komponentenfehler_05
      data DE_DCDC_NV_Komponentenfehler_05: type=uint8
    IF_DCDC_NV_Komponentenfehler_06
      data DE_DCDC_NV_Komponentenfehler_06: type=uint8
    IF_DCDC_NV_Komponentenfehler_07
      data DE_DCDC_NV_Komponentenfehler_07: type=uint8
    IF_DCDC_NV_Komponentenfehler_08
      data DE_DCDC_NV_Komponentenfehler_08: type=uint8
    IF_DCDC_NV_Komponentenfehler_09
      data DE_DCDC_NV_Komponentenfehler_09: type=uint8
    IF_DCDC_NV_Komponentenfehler_10
      data DE_DCDC_NV_Komponentenfehler_10: type=uint8
    IF_DCDC_NV_Komponentenfehler_11
      data DE_DCDC_NV_Komponentenfehler_11: type=uint8
    IF_DCDC_NV_Komponentenfehler_12
      data DE_DCDC_NV_Komponentenfehler_12: type=uint8
    IF_DCDC_NV_Komponentenfehler_13
      data DE_DCDC_NV_Komponentenfehler_13: type=uint8
    IF_DCDC_NV_Komponentenfehler_14
      data DE_DCDC_NV_Komponentenfehler_14: type=uint8
    IF_DCDC_NV_Komponentenfehler_15
      data DE_DCDC_NV_Komponentenfehler_15: type=uint8
    IF_DCDC_NV_Komponentenfehler_16
      data DE_DCDC_NV_Komponentenfehler_16: type=uint8
    IF_DCDC_NV_Komponentenfehler_17
      data DE_DCDC_NV_Komponentenfehler_17: type=uint8
    IF_DCDC_NV_Komponentenfehler_18
      data DE_DCDC_NV_Komponentenfehler_18: type=uint8
    IF_DCDC_NV_Komponentenfehler_19
      data DE_DCDC_NV_Komponentenfehler_19: type=uint8
    IF_DCDC_NV_Komponentenfehler_20
      data DE_DCDC_NV_Komponentenfehler_20: type=uint8
    IF_DCDC_NV_Komponentenfehler_21
      data DE_DCDC_NV_Komponentenfehler_21: type=uint8
    IF_DCDC_NV_Komponentenfehler_22
      data DE_DCDC_NV_Komponentenfehler_22: type=uint8
    IF_DCDC_NV_Komponentenfehler_23
      data DE_DCDC_NV_Komponentenfehler_23: type=uint8
    IF_DCDC_NV_Komponentenfehler_24
      data DE_DCDC_NV_Komponentenfehler_24: type=uint8
    IF_DCDC_NV_Komponentenfehler_25
      data DE_DCDC_NV_Komponentenfehler_25: type=uint8
    IF_DCDC_NV_Komponentenfehler_26
      data DE_DCDC_NV_Komponentenfehler_26: type=uint8
    IF_DCDC_NV_Komponentenfehler_27
      data DE_DCDC_NV_Komponentenfehler_27: type=uint8
    IF_DCDC_NV_Komponentenfehler_28
      data DE_DCDC_NV_Komponentenfehler_28: type=uint8
    IF_DCDC_NV_Komponentenfehler_29
      data DE_DCDC_NV_Komponentenfehler_29: type=uint8
    IF_DCDC_NV_Komponentenfehler_30
      data DE_DCDC_NV_Komponentenfehler_30: type=uint8
    IF_DCDC_NV_Komponentenfehler_31
      data DE_DCDC_NV_Komponentenfehler_31: type=uint8
    IF_DCDC_NV_Komponentenfehler_32
      data DE_DCDC_NV_Komponentenfehler_32: type=uint8
    IF_DCDC_NV_Komponentenfehler_33
      data DE_DCDC_NV_Komponentenfehler_33: type=uint8
    IF_DCDC_NV_Komponentenfehler_34
      data DE_DCDC_NV_Komponentenfehler_34: type=uint8
    IF_DCDC_NV_Komponentenfehler_35
      data DE_DCDC_NV_Komponentenfehler_35: type=uint8
    IF_DCDC_NV_Komponentenfehler_36
      data DE_DCDC_NV_Komponentenfehler_36: type=uint8
    IF_DCDC_NV_Komponentenfehler_37
      data DE_DCDC_NV_Komponentenfehler_37: type=uint8
    IF_DCDC_NV_Komponentenfehler_38
      data DE_DCDC_NV_Komponentenfehler_38: type=uint8
    IF_DCDC_NV_Komponentenfehler_39
      data DE_DCDC_NV_Komponentenfehler_39: type=uint8
    IF_DCDC_NV_Komponentenfehler_3_1
      data DE_DCDC_NV_Komponentenfehler_3_1: type=uint8
    IF_DCDC_NV_Komponentenfehler_3_10
      data DE_DCDC_NV_Komponentenfehler_3_10: type=uint8
    IF_DCDC_NV_Komponentenfehler_3_11
      data DE_DCDC_NV_Komponentenfehler_3_11: type=uint8
    IF_DCDC_NV_Komponentenfehler_3_12
      data DE_DCDC_NV_Komponentenfehler_3_12: type=uint8
    IF_DCDC_NV_Komponentenfehler_3_13
      data DE_DCDC_NV_Komponentenfehler_3_13: type=uint8
    IF_DCDC_NV_Komponentenfehler_3_14
      data DE_DCDC_NV_Komponentenfehler_3_14: type=uint8
    IF_DCDC_NV_Komponentenfehler_3_15
      data DE_DCDC_NV_Komponentenfehler_3_15: type=uint8
    IF_DCDC_NV_Komponentenfehler_3_16
      data DE_DCDC_NV_Komponentenfehler_3_16: type=uint8
    IF_DCDC_NV_Komponentenfehler_3_2
      data DE_DCDC_NV_Komponentenfehler_3_2: type=uint8
    IF_DCDC_NV_Komponentenfehler_3_3
      data DE_DCDC_NV_Komponentenfehler_3_3: type=uint8
    IF_DCDC_NV_Komponentenfehler_3_4
      data DE_DCDC_NV_Komponentenfehler_3_4: type=uint8
    IF_DCDC_NV_Komponentenfehler_3_5
      data DE_DCDC_NV_Komponentenfehler_3_5: type=uint8
    IF_DCDC_NV_Komponentenfehler_3_6
      data DE_DCDC_NV_Komponentenfehler_3_6: type=uint8
    IF_DCDC_NV_Komponentenfehler_3_7
      data DE_DCDC_NV_Komponentenfehler_3_7: type=uint8
    IF_DCDC_NV_Komponentenfehler_3_8
      data DE_DCDC_NV_Komponentenfehler_3_8: type=uint8
    IF_DCDC_NV_Komponentenfehler_3_9
      data DE_DCDC_NV_Komponentenfehler_3_9: type=uint8
    IF_DCDC_NV_Komponentenfehler_40
      data DE_DCDC_NV_Komponentenfehler_40: type=uint8
    IF_DCDC_NV_Komponentenfehler_41
      data DE_DCDC_NV_Komponentenfehler_41: type=uint8
    IF_DCDC_NV_Komponentenfehler_42
      data DE_DCDC_NV_Komponentenfehler_42: type=uint8
    IF_DCDC_NV_Komponentenfehler_43
      data DE_DCDC_NV_Komponentenfehler_43: type=uint8
    IF_DCDC_NV_Komponentenfehler_44
      data DE_DCDC_NV_Komponentenfehler_44: type=uint8
    IF_DCDC_NV_Komponentenfehler_45
      data DE_DCDC_NV_Komponentenfehler_45: type=uint8
    IF_DCDC_NV_Komponentenfehler_46
      data DE_DCDC_NV_Komponentenfehler_46: type=uint8
    IF_DCDC_NV_Komponentenfehler_47
      data DE_DCDC_NV_Komponentenfehler_47: type=uint8
    IF_DCDC_NV_Komponentenfehler_48
      data DE_DCDC_NV_Komponentenfehler_48: type=uint8
    IF_DCDC_NV_Komponentenfehler_49
      data DE_DCDC_NV_Komponentenfehler_49: type=uint8
    IF_DCDC_NV_Komponentenfehler_50
      data DE_DCDC_NV_Komponentenfehler_50: type=uint8
    IF_DCDC_NV_Komponentenfehler_51
      data DE_DCDC_NV_Komponentenfehler_51: type=uint8
    IF_DCDC_NV_Komponentenfehler_52
      data DE_DCDC_NV_Komponentenfehler_52: type=uint8
    IF_DCDC_NV_Komponentenfehler_53
      data DE_DCDC_NV_Komponentenfehler_53: type=uint8
    IF_DCDC_NV_Komponentenfehler_54
      data DE_DCDC_NV_Komponentenfehler_54: type=uint8
    IF_DCDC_NV_Komponentenfehler_55
      data DE_DCDC_NV_Komponentenfehler_55: type=uint8
    IF_DCDC_NV_Komponentenfehler_56
      data DE_DCDC_NV_Komponentenfehler_56: type=uint8
    IF_DCDC_NV_Komponentenfehler_57
      data DE_DCDC_NV_Komponentenfehler_57: type=uint8
    IF_DCDC_NV_Komponentenfehler_58
      data DE_DCDC_NV_Komponentenfehler_58: type=uint8
    IF_DCDC_NV_Komponentenfehler_59
      data DE_DCDC_NV_Komponentenfehler_59: type=uint8
    IF_DCDC_NV_Komponentenfehler_60
      data DE_DCDC_NV_Komponentenfehler_60: type=uint8
    IF_DCDC_NV_Komponentenfehler_61
      data DE_DCDC_NV_Komponentenfehler_61: type=uint8
    IF_DCDC_NV_Komponentenfehler_62
      data DE_DCDC_NV_Komponentenfehler_62: type=uint8
    IF_DCDC_NV_Komponentenfehler_63
      data DE_DCDC_NV_Komponentenfehler_63: type=uint8
    IF_DCDC_NV_Komponentenfehler_64
      data DE_DCDC_NV_Komponentenfehler_64: type=uint8
    IF_DCDC_NV_Komponentenfehler_65
      data DE_DCDC_NV_Komponentenfehler_65: type=uint8
    IF_DCDC_NV_Komponentenfehler_66
      data DE_DCDC_NV_Komponentenfehler_66: type=uint8
    IF_DCDC_NV_Komponentenfehler_67
      data DE_DCDC_NV_Komponentenfehler_67: type=uint8
    IF_DCDC_NV_Komponentenfehler_68
      data DE_DCDC_NV_Komponentenfehler_68: type=uint8
    IF_DCDC_NV_Komponentenfehler_69
      data DE_DCDC_NV_Komponentenfehler_69: type=uint8
    IF_DCDC_NV_Komponentenfehler_70
      data DE_DCDC_NV_Komponentenfehler_70: type=uint8
    IF_DCDC_NV_Komponentenfehler_71
      data DE_DCDC_NV_Komponentenfehler_71: type=uint8
    IF_DCDC_NV_Komponentenfehler_72
      data DE_DCDC_NV_Komponentenfehler_72: type=uint8
    IF_DCDC_NV_Komponentenfehler_73
      data DE_DCDC_NV_Komponentenfehler_73: type=uint8
    IF_DCDC_NV_Komponentenfehler_74
      data DE_DCDC_NV_Komponentenfehler_74: type=uint8
    IF_DCDC_NV_Komponentenfehler_75
      data DE_DCDC_NV_Komponentenfehler_75: type=uint8
    IF_DCDC_NV_Komponentenfehler_76
      data DE_DCDC_NV_Komponentenfehler_76: type=uint8
    IF_DCDC_NV_Komponentenfehler_77
      data DE_DCDC_NV_Komponentenfehler_77: type=uint8
    IF_DCDC_NV_Komponentenfehler_78
      data DE_DCDC_NV_Komponentenfehler_78: type=uint8
    IF_DCDC_NV_Komponentenfehler_79
      data DE_DCDC_NV_Komponentenfehler_79: type=uint8
    IF_DCDC_NV_Komponentenfehler_80
      data DE_DCDC_NV_Komponentenfehler_80: type=uint8
    IF_DCDC_NV_Komponentenfehler_VLD
      data DE_DCDC_NV_Komponentenfehler_VLD: type=boolean
    IF_DEV_Hybrid_01_Req_00_FD_Data
      data DE_DEV_Hybrid_01_Req_00_FD_Data: type=DEV_Hybrid_01_Req_00_FD_Data
    IF_DEV_Hybrid_01_Resp_FF_FD_Data
      data DE_DEV_Hybrid_01_Resp_FF_FD_Data: type=DEV_Hybrid_01_Resp_FF_FD_Data
    IF_DS_Hybrid_01_ConfDTCChanged
      data DE_DS_Hybrid_01_ConfDTCChanged: type=boolean
    IF_DS_Hybrid_01_DiagAdr
      data DE_DS_Hybrid_01_DiagAdr: type=uint16
    IF_DS_Hybrid_01_IdentValid
      data DE_DS_Hybrid_01_IdentValid: type=boolean
    IF_DS_Hybrid_01_Lokalaktiv
      data DE_DS_Hybrid_01_Lokalaktiv: type=boolean
    IF_DS_Hybrid_01_MemSel10Changed
      data DE_DS_Hybrid_01_MemSel10Changed: type=boolean
    IF_DS_Hybrid_01_MemSelChanged
      data DE_DS_Hybrid_01_MemSelChanged: type=boolean
    IF_DS_Hybrid_01_StMemChanged
      data DE_DS_Hybrid_01_StMemChanged: type=boolean
    IF_DS_Hybrid_01_Subsystemaktiv
      data DE_DS_Hybrid_01_Subsystemaktiv: type=boolean
    IF_DS_Hybrid_01_TestFailedChanged
      data DE_DS_Hybrid_01_TestFailedChanged: type=boolean
    IF_DS_Hybrid_01_WIRChanged
      data DE_DS_Hybrid_01_WIRChanged: type=boolean
    IF_DW_Kilometerstand
      data DE_DW_Kilometerstand: type=uint32
    IF_EKK_HVK_EoHVL_Status
      data DE_EKK_HVK_EoHVL_Status: type=uint8
    IF_HVEM_BMC_CHA_Wunschleistung
      data DE_HVEM_BMC_CHA_Wunschleistung: type=uint16
    IF_HVEM_BMC_CHA_Wunschleistung_02
      data DE_HVEM_BMC_CHA_Wunschleistung_02: type=uint16
    IF_HVEM_MMTR_State
      data DE_HVEM_MMTR_State: type=uint8
    IF_HVEM_SystemMinLeistungsgrenze
      data DE_HVEM_SystemMinLeistungsgrenze: type=uint8
    IF_HVK_03_BZ
      data DE_HVK_03_BZ: type=uint8
    IF_HVK_03_CRC
      data DE_HVK_03_CRC: type=uint8
    IF_HVK_BMC_Sollmodus
      data DE_HVK_BMC_Sollmodus: type=uint8
    IF_HVK_BMC_Spannung_Anf
      data DE_HVK_BMC_Spannung_Anf: type=uint8
    IF_HVK_Iso_Messung_Start
      data DE_HVK_Iso_Messung_Start: type=uint8
    IF_HVK_Istmodus_Anf
      data DE_HVK_Istmodus_Anf: type=boolean
    IF_HVLE_IstSpannung_HV
      data DE_HVLE_IstSpannung_HV: type=uint16
    IF_HVLE_OBG_IstModus
      data DE_HVLE_OBG_IstModus: type=uint8
    IF_HVLM_14_BZ
      data DE_HVLM_14_BZ: type=uint8
    IF_HVLM_14_CRC
      data DE_HVLM_14_CRC: type=uint8
    IF_HVLM_BCAM_Aktiv
      data DE_HVLM_BCAM_Aktiv: type=boolean
    IF_HVLM_BidiLadeModus
      data DE_HVLM_BidiLadeModus: type=uint8
    IF_HVLM_DC_Aufstartmodus
      data DE_HVLM_DC_Aufstartmodus: type=uint8
    IF_HVLM_Start_Pulserkennung
      data DE_HVLM_Start_Pulserkennung: type=boolean
    IF_HVLM_Steckerstatus
      data DE_HVLM_Steckerstatus: type=uint8
    IF_HVLM_ZustandLadeablauf
      data DE_HVLM_ZustandLadeablauf: type=uint8
    IF_Hybrid_01_Indc_StChk
      data DE_Hybrid_01_Indc_StChk: type=boolean
    IF_Hybrid_01_Indc_StFail
      data DE_Hybrid_01_Indc_StFail: type=boolean
    IF_Hybrid_01_KD_Fehler
      data DE_Hybrid_01_KD_Fehler: type=boolean
    IF_Hybrid_01_KompSchutz
      data DE_Hybrid_01_KompSchutz: type=boolean
    IF_Hybrid_01_Nachlauftyp
      data DE_Hybrid_01_Nachlauftyp: type=uint8
    IF_Hybrid_01_OBD_Lampe_Anf
      data DE_Hybrid_01_OBD_Lampe_Anf: type=boolean
    IF_Hybrid_01_SNI_10
      data DE_Hybrid_01_SNI_10: type=uint16
    IF_ISO_ALL_01_Req_Data
      data DE_ISO_ALL_01_Req_Data: type=uint64
    IF_KN_Hybrid_01_BusKnockOut
      data DE_KN_Hybrid_01_BusKnockOut: type=uint8
    IF_KN_Hybrid_01_BusKnockOutTimer
      data DE_KN_Hybrid_01_BusKnockOutTimer: type=uint8
    IF_KN_Hybrid_01_DiagPfad_V12
      data DE_KN_Hybrid_01_DiagPfad_V12: type=boolean
    IF_KN_Hybrid_01_ECUKnockOut
      data DE_KN_Hybrid_01_ECUKnockOut: type=uint8
    IF_KN_Hybrid_01_ECUKnockOutTimer
      data DE_KN_Hybrid_01_ECUKnockOutTimer: type=uint8
    IF_KS_Hybrid_01_ChK
      data DE_KS_Hybrid_01_ChK: type=uint64
    IF_KS_Hybrid_01_ChK_IKACtr
      data DE_KS_Hybrid_01_ChK_IKACtr: type=uint8
    IF_KS_Hybrid_01_ChK_SID
      data DE_KS_Hybrid_01_ChK_SID: type=uint16
    IF_KS_Hybrid_01_ChM
      data DE_KS_Hybrid_01_ChM: type=uint64
    IF_KS_Hybrid_01_ChM_IKACtr
      data DE_KS_Hybrid_01_ChM_IKACtr: type=uint8
    IF_KS_Hybrid_01_ChM_SID
      data DE_KS_Hybrid_01_ChM_SID: type=uint16
    IF_KS_Hybrid_01_ReK
      data DE_KS_Hybrid_01_ReK: type=uint64
    IF_KS_Hybrid_01_ReK_IKACtr
      data DE_KS_Hybrid_01_ReK_IKACtr: type=uint8
    IF_KS_Hybrid_01_ReK_SID
      data DE_KS_Hybrid_01_ReK_SID: type=uint16
    IF_KS_Hybrid_01_ReM
      data DE_KS_Hybrid_01_ReM: type=uint64
    IF_KS_Hybrid_01_ReM_IKACtr
      data DE_KS_Hybrid_01_ReM_IKACtr: type=uint8
    IF_KS_Hybrid_01_ReM_SID
      data DE_KS_Hybrid_01_ReM_SID: type=uint16
    IF_KS_Hybrid_01_Req_ErrCtr
      data DE_KS_Hybrid_01_Req_ErrCtr: type=uint8
    IF_KS_Hybrid_01_Req_IKA_Retry
      data DE_KS_Hybrid_01_Req_IKA_Retry: type=boolean
    IF_KS_Hybrid_01_Req_Prio
      data DE_KS_Hybrid_01_Req_Prio: type=boolean
    IF_KS_Hybrid_01_Req_SID
      data DE_KS_Hybrid_01_Req_SID: type=uint16
    IF_KS_Hybrid_01_Req_SWMaj
      data DE_KS_Hybrid_01_Req_SWMaj: type=uint8
    IF_KS_Hybrid_01_Req_SWMin
      data DE_KS_Hybrid_01_Req_SWMin: type=uint8
    IF_KS_Hybrid_01_Req_SWPat
      data DE_KS_Hybrid_01_Req_SWPat: type=uint8
    IF_KS_Hybrid_01_Req_VKMS_Err
      data DE_KS_Hybrid_01_Req_VKMS_Err: type=boolean
    IF_KST_KL_15
      data DE_KST_KL_15: type=boolean
    IF_MM_PropulsionSystemActive
      data DE_MM_PropulsionSystemActive: type=boolean
    IF_NM_aktiv_Konditionierungsbedarf
      data DE_NM_aktiv_Konditionierungsbedarf: type=boolean
    IF_NM_aktiv_SubbusSteuerung_BMC_HV
      data DE_NM_aktiv_SubbusSteuerung_BMC_HV: type=boolean
    IF_NM_AWC_FCAB
      data DE_NM_AWC_FCAB: type=uint64
    IF_NM_Dummy01_NM_State
      data DE_NM_Dummy01_NM_State: type=uint8
    IF_NM_Gateway_FCAB
      data DE_NM_Gateway_FCAB: type=uint64
    IF_NM_HVZB_FCAB
      data DE_NM_HVZB_FCAB: type=uint64
    IF_NM_Hybrid_01_CAB_V12
      data DE_NM_Hybrid_01_CAB_V12: type=uint32
    IF_NM_Hybrid_01_CBV_AWB
      data DE_NM_Hybrid_01_CBV_AWB: type=boolean
    IF_NM_Hybrid_01_CBV_CRI
      data DE_NM_Hybrid_01_CBV_CRI: type=boolean
    IF_NM_Hybrid_01_FCAB
      data DE_NM_Hybrid_01_FCAB: type=uint64
    IF_NM_Hybrid_01_FCIB
      data DE_NM_Hybrid_01_FCIB: type=uint64
    IF_NM_Hybrid_01_Lokalaktiv
      data DE_NM_Hybrid_01_Lokalaktiv: type=boolean
    IF_NM_Hybrid_01_NM_aktiv_Diag
      data DE_NM_Hybrid_01_NM_aktiv_Diag: type=boolean
    IF_NM_Hybrid_01_NM_aktiv_KL15
      data DE_NM_Hybrid_01_NM_aktiv_KL15: type=boolean
    IF_NM_Hybrid_01_NM_aktiv_Tmin
      data DE_NM_Hybrid_01_NM_aktiv_Tmin: type=boolean
    IF_NM_Hybrid_01_NM_State
      data DE_NM_Hybrid_01_NM_State: type=uint8
    IF_NM_Hybrid_01_SNI_10
      data DE_NM_Hybrid_01_SNI_10: type=uint16
    IF_NM_Hybrid_01_Subsystemaktiv
      data DE_NM_Hybrid_01_Subsystemaktiv: type=boolean
    IF_NM_Hybrid_01_UDS_CC
      data DE_NM_Hybrid_01_UDS_CC: type=boolean
    IF_NM_Hybrid_01_Wakeup_V12
      data DE_NM_Hybrid_01_Wakeup_V12: type=uint8
    IF_NM_Ladegeraet_FCAB
      data DE_NM_Ladegeraet_FCAB: type=uint64
    IF_NM_SACID_1_FCAB
      data DE_NM_SACID_1_FCAB: type=uint64
    IF_NM_SACID_2_FCAB
      data DE_NM_SACID_2_FCAB: type=uint64
    IF_NVEM_Abschaltstufe
      data DE_NVEM_Abschaltstufe: type=uint8
    IF_OBD_Abs_Pedal_Pos
      data DE_OBD_Abs_Pedal_Pos: type=uint8
    IF_OBD_Aussen_Temp_gef
      data DE_OBD_Aussen_Temp_gef: type=uint8
    IF_OBD_Barometric_Pressure
      data DE_OBD_Barometric_Pressure: type=uint8
    IF_OBD_Calc_Load_Val
      data DE_OBD_Calc_Load_Val: type=uint8
    IF_OBD_ClearMem_Inhibit
      data DE_OBD_ClearMem_Inhibit: type=boolean
    IF_OBD_Driving_Cycle
      data DE_OBD_Driving_Cycle: type=boolean
    IF_OBD_Eng_Cool_Temp
      data DE_OBD_Eng_Cool_Temp: type=uint8
    IF_OBD_Engine_RPM
      data DE_OBD_Engine_RPM: type=uint16
    IF_OBD_Kaltstart_Denominator
      data DE_OBD_Kaltstart_Denominator: type=boolean
    IF_OBD_Minimum_Trip
      data DE_OBD_Minimum_Trip: type=boolean
    IF_OBD_Normed_Trip
      data DE_OBD_Normed_Trip: type=boolean
    IF_OBD_NumDcyMilOnReq
      data DE_OBD_NumDcyMilOnReq: type=uint8
    IF_OBD_QBit_Aussen_Temp
      data DE_OBD_QBit_Aussen_Temp: type=boolean
    IF_OBD_Sperrung_IUMPR
      data DE_OBD_Sperrung_IUMPR: type=boolean
    IF_OBD_Sperrung_Kaltstart_Denom
      data DE_OBD_Sperrung_Kaltstart_Denom: type=boolean
    IF_OBD_Typ
      data DE_OBD_Typ: type=boolean
    IF_OBD_Warm_Up_Cycle
      data DE_OBD_Warm_Up_Cycle: type=boolean
    IF_OBDProtocol_Hybrid_01
      data DE_OBDProtocol_Hybrid_01: type=uint8
    IF_OBDProtocol_req
      data DE_OBDProtocol_req: type=uint8
    IF_OnlineRemoteUpdateControlA
      data DE_OnlineRemoteUpdateControlA: type=uint8
    IF_OnlineRemoteUpdateControlD
      data DE_OnlineRemoteUpdateControlD: type=uint8
    IF_OnlineRemoteUpdateControlOldA
      data DE_OnlineRemoteUpdateControlOldA: type=uint8
    IF_OnlineRemoteUpdateControlOldD
      data DE_OnlineRemoteUpdateControlOldD: type=uint8
    IF_ORU_Control_A_01_BZ
      data DE_ORU_Control_A_01_BZ: type=uint8
    IF_ORU_Control_A_01_CRC
      data DE_ORU_Control_A_01_CRC: type=uint8
    IF_ORU_Control_D_01_BZ
      data DE_ORU_Control_D_01_BZ: type=uint8
    IF_ORU_Control_D_01_CRC
      data DE_ORU_Control_D_01_CRC: type=uint8
    IF_ORU_Status
      data DE_ORU_Status: type=uint8
    IF_OruControlReleaseA
      data DE_OruControlReleaseA: type=uint16
    IF_OruControlReleaseD
      data DE_OruControlReleaseD: type=uint16
    IF_OTAMC_D_01_BZ
      data DE_OTAMC_D_01_BZ: type=uint8
    IF_OTAMC_D_01_CRC
      data DE_OTAMC_D_01_CRC: type=uint8
    IF_OTP_Aussen_Temp_OBD
      data DE_OTP_Aussen_Temp_OBD: type=boolean
    IF_OTP_Aussen_Temp_ungef
      data DE_OTP_Aussen_Temp_ungef: type=uint8
    IF_PCM_BMC_VTD_Freeze_Req
      data DE_PCM_BMC_VTD_Freeze_Req: type=uint8
    IF_PCM_BMC_VTD_LifeTimeReset_Req
      data DE_PCM_BMC_VTD_LifeTimeReset_Req: type=uint8
    IF_PCM_BMC_VTD_LifeTimeReset_Resp
      data DE_PCM_BMC_VTD_LifeTimeReset_Resp: type=uint8
    IF_PCM_BMC_VTD_RecentReset_Req
      data DE_PCM_BMC_VTD_RecentReset_Req: type=uint8
    IF_SG_BJB_10
      data DE_SG_BJB_10: type=AT_SG_BJB_10
    IF_SG_BJB_11
      data DE_SG_BJB_11: type=AT_SG_BJB_11
    IF_SG_BJB_12
      data DE_SG_BJB_12: type=AT_SG_BJB_12
    IF_SG_BJB_13
      data DE_SG_BJB_13: type=AT_SG_BJB_13
    IF_SG_HVK_03
      data DE_SG_HVK_03: type=AT_SG_HVK_03
    IF_SG_HVLM_14
      data DE_SG_HVLM_14: type=AT_SG_HVLM_14
    IF_SG_KS_Hybrid_01_Challenge_M
      data DE_SG_KS_Hybrid_01_Challenge_M: type=AT_SG_KS_Hybrid_01_Challenge_M
    IF_SG_KS_Hybrid_01_Response_M
      data DE_SG_KS_Hybrid_01_Response_M: type=AT_SG_KS_Hybrid_01_Response_M
    IF_SG_ORU_Control_A_01
      data DE_SG_ORU_Control_A_01: type=AT_SG_ORU_Control_A_01
    IF_SG_ORU_Control_D_01
      data DE_SG_ORU_Control_D_01: type=AT_SG_ORU_Control_D_01
    IF_SG_OTAMC_D_01
      data DE_SG_OTAMC_D_01: type=AT_SG_OTAMC_D_01
    IF_SG_UI1_01
      data DE_SG_UI1_01: type=AT_SG_UI1_01
    IF_SG_UI1_02
      data DE_SG_UI1_02: type=AT_SG_UI1_02
    IF_SG_UI2_01
      data DE_SG_UI2_01: type=AT_SG_UI2_01
    IF_SG_UI2_02
      data DE_SG_UI2_02: type=AT_SG_UI2_02
    IF_SG_UI2_03
      data DE_SG_UI2_03: type=AT_SG_UI2_03
    IF_SI_NWDF
      data DE_SI_NWDF: type=boolean
    IF_SI_NWDF_30
      data DE_SI_NWDF_30: type=boolean
    IF_SI_P_Mode
      data DE_SI_P_Mode: type=boolean
    IF_SI_P_Mode_gueltig
      data DE_SI_P_Mode_gueltig: type=boolean
    IF_SI_T_Mode
      data DE_SI_T_Mode: type=boolean
    IF_SOK_ungeschuetzte_Zeit
      data DE_SOK_ungeschuetzte_Zeit: type=uint64
    IF_SOK_Zeit_Hybrid_01_Challenge
      data DE_SOK_Zeit_Hybrid_01_Challenge: type=uint64
    IF_SOK_Zeit_Hybrid_01_Zeit
      data DE_SOK_Zeit_Hybrid_01_Zeit: type=uint64
    IF_TME_Batt_Kond_Verf
      data DE_TME_Batt_Kond_Verf: type=uint8
    IF_TME_Therm_IstLeistung_HVBatterie
      data DE_TME_Therm_IstLeistung_HVBatterie: type=uint16
    IF_UH_Jahr
      data DE_UH_Jahr: type=uint8
    IF_UH_Minute
      data DE_UH_Minute: type=uint8
    IF_UH_Monat
      data DE_UH_Monat: type=uint8
    IF_UH_Sekunde
      data DE_UH_Sekunde: type=uint8
    IF_UH_Stunde
      data DE_UH_Stunde: type=uint8
    IF_UH_Tag
      data DE_UH_Tag: type=uint8
    IF_UI1_Iso_Neg
      data DE_UI1_Iso_Neg: type=uint16
    IF_UI1_Iso_Pos
      data DE_UI1_Iso_Pos: type=uint16
    IF_UI1_Iso_Status
      data DE_UI1_Iso_Status: type=uint8
    IF_UI1_KL30_Spannung
      data DE_UI1_KL30_Spannung: type=uint8
    IF_UI1_KompFehlerModus2_01
      data DE_UI1_KompFehlerModus2_01: type=uint8
    IF_UI1_KompFehlerModus2_02
      data DE_UI1_KompFehlerModus2_02: type=uint8
    IF_UI1_KompFehlerModus2_03
      data DE_UI1_KompFehlerModus2_03: type=uint8
    IF_UI1_KompFehlerModus2_04
      data DE_UI1_KompFehlerModus2_04: type=uint8
    IF_UI1_KompFehlerModus2_05
      data DE_UI1_KompFehlerModus2_05: type=uint8
    IF_UI1_KompFehlerModus2_06
      data DE_UI1_KompFehlerModus2_06: type=uint8
    IF_UI1_KompFehlerModus2_07
      data DE_UI1_KompFehlerModus2_07: type=uint8
    IF_UI1_KompFehlerModus2_08
      data DE_UI1_KompFehlerModus2_08: type=uint8
    IF_UI1_KompFehlerModus2_09
      data DE_UI1_KompFehlerModus2_09: type=uint8
    IF_UI1_KompFehlerModus2_10
      data DE_UI1_KompFehlerModus2_10: type=uint8
    IF_UI1_KompFehlerModus2_11
      data DE_UI1_KompFehlerModus2_11: type=uint8
    IF_UI1_KompFehlerModus2_12
      data DE_UI1_KompFehlerModus2_12: type=uint8
    IF_UI1_KompFehlerModus2_13
      data DE_UI1_KompFehlerModus2_13: type=uint8
    IF_UI1_KompFehlerModus2_14
      data DE_UI1_KompFehlerModus2_14: type=uint8
    IF_UI1_KompFehlerModus2_15
      data DE_UI1_KompFehlerModus2_15: type=uint8
    IF_UI1_KompFehlerModus2_16
      data DE_UI1_KompFehlerModus2_16: type=uint8
    IF_UI1_KompFehlerModus2_17
      data DE_UI1_KompFehlerModus2_17: type=uint8
    IF_UI1_KompFehlerModus2_18
      data DE_UI1_KompFehlerModus2_18: type=uint8
    IF_UI1_KompFehlerModus2_19
      data DE_UI1_KompFehlerModus2_19: type=uint8
    IF_UI1_KompFehlerModus2_20
      data DE_UI1_KompFehlerModus2_20: type=uint8
    IF_UI1_KompFehlerModus2_21
      data DE_UI1_KompFehlerModus2_21: type=uint8
    IF_UI1_KompFehlerModus2_22
      data DE_UI1_KompFehlerModus2_22: type=uint8
    IF_UI1_KompFehlerModus2_23
      data DE_UI1_KompFehlerModus2_23: type=uint8
    IF_UI1_KompFehlerModus2_24
      data DE_UI1_KompFehlerModus2_24: type=uint8
    IF_UI1_KompFehlerModus2_25
      data DE_UI1_KompFehlerModus2_25: type=uint8
    IF_UI1_KompFehlerModus2_26
      data DE_UI1_KompFehlerModus2_26: type=uint8
    IF_UI1_KompFehlerModus4_01
      data DE_UI1_KompFehlerModus4_01: type=uint8
    IF_UI1_KompFehlerModus4_02
      data DE_UI1_KompFehlerModus4_02: type=uint8
    IF_UI1_KompFehlerModus4_03
      data DE_UI1_KompFehlerModus4_03: type=uint8
    IF_UI1_KompFehlerModus4_04
      data DE_UI1_KompFehlerModus4_04: type=uint8
    IF_UI1_KompFehlerModus4_05
      data DE_UI1_KompFehlerModus4_05: type=uint8
    IF_UI1_KompFehlerModus4_06
      data DE_UI1_KompFehlerModus4_06: type=uint8
    IF_UI1_KompFehlerModus4_07
      data DE_UI1_KompFehlerModus4_07: type=uint8
    IF_UI1_KompFehlerModus4_08
      data DE_UI1_KompFehlerModus4_08: type=uint8
    IF_UI1_KompFehlerModus4_09
      data DE_UI1_KompFehlerModus4_09: type=uint8
    IF_UI1_KompFehlerModus4_10
      data DE_UI1_KompFehlerModus4_10: type=uint8
    IF_UI1_KompFehlerModus4_11
      data DE_UI1_KompFehlerModus4_11: type=uint8
    IF_UI1_KompFehlerModus4_12
      data DE_UI1_KompFehlerModus4_12: type=uint8
    IF_UI1_KompFehlerModus4_13
      data DE_UI1_KompFehlerModus4_13: type=uint8
    IF_UI1_KompFehlerModus4_14
      data DE_UI1_KompFehlerModus4_14: type=uint8
    IF_UI1_KompFehlerModus4_15
      data DE_UI1_KompFehlerModus4_15: type=uint8
    IF_UI1_KompFehlerModus4_16
      data DE_UI1_KompFehlerModus4_16: type=uint8
    IF_UI1_Spannung1
      data DE_UI1_Spannung1: type=uint16
    IF_UI1_Spannung1_Schalt_Status
      data DE_UI1_Spannung1_Schalt_Status: type=uint8
    IF_UI1_Spannung2
      data DE_UI1_Spannung2: type=uint16
    IF_UI1_Spannung2_Schalt_Status
      data DE_UI1_Spannung2_Schalt_Status: type=uint8
    IF_UI1_Spannung3
      data DE_UI1_Spannung3: type=uint16
    IF_UI1_Spannung4
      data DE_UI1_Spannung4: type=uint16
    IF_UI1_Spannung5
      data DE_UI1_Spannung5: type=uint16
    IF_UI1_Spannung6
      data DE_UI1_Spannung6: type=uint16
    IF_UI1_Status
      data DE_UI1_Status: type=boolean
    IF_UI1_Strom
      data DE_UI1_Strom: type=uint32
    IF_UI1_Stromintegral_Entladen
      data DE_UI1_Stromintegral_Entladen: type=uint16
    IF_UI1_Stromintegral_Laden
      data DE_UI1_Stromintegral_Laden: type=uint16
    IF_UI1_Temperatur_1
      data DE_UI1_Temperatur_1: type=uint8
    IF_UI1_Temperatur_2
      data DE_UI1_Temperatur_2: type=uint8
    IF_UI2_HW_Crashleitung_Status
      data DE_UI2_HW_Crashleitung_Status: type=uint8
    IF_UI2_KL30_Spannung
      data DE_UI2_KL30_Spannung: type=uint8
    IF_UI2_KompFehlerModus2_01
      data DE_UI2_KompFehlerModus2_01: type=uint8
    IF_UI2_KompFehlerModus2_02
      data DE_UI2_KompFehlerModus2_02: type=uint8
    IF_UI2_KompFehlerModus2_03
      data DE_UI2_KompFehlerModus2_03: type=uint8
    IF_UI2_KompFehlerModus2_04
      data DE_UI2_KompFehlerModus2_04: type=uint8
    IF_UI2_KompFehlerModus2_05
      data DE_UI2_KompFehlerModus2_05: type=uint8
    IF_UI2_KompFehlerModus2_06
      data DE_UI2_KompFehlerModus2_06: type=uint8
    IF_UI2_KompFehlerModus2_07
      data DE_UI2_KompFehlerModus2_07: type=uint8
    IF_UI2_KompFehlerModus2_08
      data DE_UI2_KompFehlerModus2_08: type=uint8
    IF_UI2_KompFehlerModus2_09
      data DE_UI2_KompFehlerModus2_09: type=uint8
    IF_UI2_KompFehlerModus2_10
      data DE_UI2_KompFehlerModus2_10: type=uint8
    IF_UI2_KompFehlerModus2_11
      data DE_UI2_KompFehlerModus2_11: type=uint8
    IF_UI2_KompFehlerModus2_12
      data DE_UI2_KompFehlerModus2_12: type=uint8
    IF_UI2_KompFehlerModus2_13
      data DE_UI2_KompFehlerModus2_13: type=uint8
    IF_UI2_KompFehlerModus2_14
      data DE_UI2_KompFehlerModus2_14: type=uint8
    IF_UI2_KompFehlerModus2_15
      data DE_UI2_KompFehlerModus2_15: type=uint8
    IF_UI2_KompFehlerModus2_16
      data DE_UI2_KompFehlerModus2_16: type=uint8
    IF_UI2_KompFehlerModus2_17
      data DE_UI2_KompFehlerModus2_17: type=uint8
    IF_UI2_KompFehlerModus2_18
      data DE_UI2_KompFehlerModus2_18: type=uint8
    IF_UI2_KompFehlerModus2_19
      data DE_UI2_KompFehlerModus2_19: type=uint8
    IF_UI2_KompFehlerModus2_20
      data DE_UI2_KompFehlerModus2_20: type=uint8
    IF_UI2_KompFehlerModus2_21
      data DE_UI2_KompFehlerModus2_21: type=uint8
    IF_UI2_KompFehlerModus2_22
      data DE_UI2_KompFehlerModus2_22: type=uint8
    IF_UI2_KompFehlerModus2_23
      data DE_UI2_KompFehlerModus2_23: type=uint8
    IF_UI2_KompFehlerModus2_24
      data DE_UI2_KompFehlerModus2_24: type=uint8
    IF_UI2_KompFehlerModus2_25
      data DE_UI2_KompFehlerModus2_25: type=uint8
    IF_UI2_KompFehlerModus2_26
      data DE_UI2_KompFehlerModus2_26: type=uint8
    IF_UI2_KompFehlerModus4_01
      data DE_UI2_KompFehlerModus4_01: type=uint8
    IF_UI2_KompFehlerModus4_02
      data DE_UI2_KompFehlerModus4_02: type=uint8
    IF_UI2_KompFehlerModus4_03
      data DE_UI2_KompFehlerModus4_03: type=uint8
    IF_UI2_KompFehlerModus4_04
      data DE_UI2_KompFehlerModus4_04: type=uint8
    IF_UI2_KompFehlerModus4_05
      data DE_UI2_KompFehlerModus4_05: type=uint8
    IF_UI2_KompFehlerModus4_06
      data DE_UI2_KompFehlerModus4_06: type=uint8
    IF_UI2_KompFehlerModus4_07
      data DE_UI2_KompFehlerModus4_07: type=uint8
    IF_UI2_KompFehlerModus4_08
      data DE_UI2_KompFehlerModus4_08: type=uint8
    IF_UI2_KompFehlerModus4_09
      data DE_UI2_KompFehlerModus4_09: type=uint8
    IF_UI2_KompFehlerModus4_10
      data DE_UI2_KompFehlerModus4_10: type=uint8
    IF_UI2_KompFehlerModus4_11
      data DE_UI2_KompFehlerModus4_11: type=uint8
    IF_UI2_KompFehlerModus4_12
      data DE_UI2_KompFehlerModus4_12: type=uint8
    IF_UI2_KompFehlerModus4_13
      data DE_UI2_KompFehlerModus4_13: type=uint8
    IF_UI2_KompFehlerModus4_14
      data DE_UI2_KompFehlerModus4_14: type=uint8
    IF_UI2_KompFehlerModus4_15
      data DE_UI2_KompFehlerModus4_15: type=uint8
    IF_UI2_KompFehlerModus4_16
      data DE_UI2_KompFehlerModus4_16: type=uint8
    IF_UI2_Pyro_Status
      data DE_UI2_Pyro_Status: type=uint8
    IF_UI2_Spannung1
      data DE_UI2_Spannung1: type=uint16
    IF_UI2_Spannung1_Schalt_Status
      data DE_UI2_Spannung1_Schalt_Status: type=uint8
    IF_UI2_Spannung2
      data DE_UI2_Spannung2: type=uint16
    IF_UI2_Spannung2_Schalt_Status
      data DE_UI2_Spannung2_Schalt_Status: type=uint8
    IF_UI2_Spannung3
      data DE_UI2_Spannung3: type=uint16
    IF_UI2_Spannung4
      data DE_UI2_Spannung4: type=uint16
    IF_UI2_Spannung5
      data DE_UI2_Spannung5: type=uint16
    IF_UI2_Spannung6
      data DE_UI2_Spannung6: type=uint16
    IF_UI2_Status
      data DE_UI2_Status: type=boolean
    IF_UI2_Strom
      data DE_UI2_Strom: type=uint32
    IF_UI2_Stromintegral_Entladen
      data DE_UI2_Stromintegral_Entladen: type=uint16
    IF_UI2_Stromintegral_Laden
      data DE_UI2_Stromintegral_Laden: type=uint16
    IF_UI2_Temperatur_1
      data DE_UI2_Temperatur_1: type=uint8
    IF_UI2_Temperatur_2
      data DE_UI2_Temperatur_2: type=uint8
    IF_UI2Sens01_CALID_Index_01
      data DE_UI2Sens01_CALID_Index_01: type=uint8
    IF_UI2Sens01_CALID_Index_02
      data DE_UI2Sens01_CALID_Index_02: type=uint8
    IF_UI2Sens01_CALID_Index_03
      data DE_UI2Sens01_CALID_Index_03: type=uint8
    IF_UI2Sens01_CALID_Index_04
      data DE_UI2Sens01_CALID_Index_04: type=uint8
    IF_UI2Sens01_CALID_Index_05
      data DE_UI2Sens01_CALID_Index_05: type=uint8
    IF_UI2Sens01_CALID_Index_06
      data DE_UI2Sens01_CALID_Index_06: type=uint8
    IF_UI2Sens01_CALID_Index_07
      data DE_UI2Sens01_CALID_Index_07: type=uint8
    IF_UI2Sens01_CALID_Index_08
      data DE_UI2Sens01_CALID_Index_08: type=uint8
    IF_UI2Sens01_CALID_Index_09
      data DE_UI2Sens01_CALID_Index_09: type=uint8
    IF_UI2Sens01_CALID_Index_10
      data DE_UI2Sens01_CALID_Index_10: type=uint8
    IF_UI2Sens01_CALID_Index_11
      data DE_UI2Sens01_CALID_Index_11: type=uint8
    IF_UI2Sens01_CALID_Index_12
      data DE_UI2Sens01_CALID_Index_12: type=uint8
    IF_UI2Sens01_CALID_Index_13
      data DE_UI2Sens01_CALID_Index_13: type=uint8
    IF_UI2Sens01_CALID_Index_14
      data DE_UI2Sens01_CALID_Index_14: type=uint8
    IF_UI2Sens01_CALID_Index_15
      data DE_UI2Sens01_CALID_Index_15: type=uint8
    IF_UI2Sens01_CALID_Index_16
      data DE_UI2Sens01_CALID_Index_16: type=uint8
    IF_UI2Sens01_CVN_Byte_1
      data DE_UI2Sens01_CVN_Byte_1: type=uint8
    IF_UI2Sens01_CVN_Byte_2
      data DE_UI2Sens01_CVN_Byte_2: type=uint8
    IF_UI2Sens01_CVN_Byte_3
      data DE_UI2Sens01_CVN_Byte_3: type=uint8
    IF_UI2Sens01_CVN_Byte_4
      data DE_UI2Sens01_CVN_Byte_4: type=uint8
    IF_UI2Sens01_CVN_VLD
      data DE_UI2Sens01_CVN_VLD: type=boolean
    IF_UI2Sens01_ErrMem_State
      data DE_UI2Sens01_ErrMem_State: type=uint8
    IF_UI2Sens02_CALID_Index_01
      data DE_UI2Sens02_CALID_Index_01: type=uint8
    IF_UI2Sens02_CALID_Index_02
      data DE_UI2Sens02_CALID_Index_02: type=uint8
    IF_UI2Sens02_CALID_Index_03
      data DE_UI2Sens02_CALID_Index_03: type=uint8
    IF_UI2Sens02_CALID_Index_04
      data DE_UI2Sens02_CALID_Index_04: type=uint8
    IF_UI2Sens02_CALID_Index_05
      data DE_UI2Sens02_CALID_Index_05: type=uint8
    IF_UI2Sens02_CALID_Index_06
      data DE_UI2Sens02_CALID_Index_06: type=uint8
    IF_UI2Sens02_CALID_Index_07
      data DE_UI2Sens02_CALID_Index_07: type=uint8
    IF_UI2Sens02_CALID_Index_08
      data DE_UI2Sens02_CALID_Index_08: type=uint8
    IF_UI2Sens02_CALID_Index_09
      data DE_UI2Sens02_CALID_Index_09: type=uint8
    IF_UI2Sens02_CALID_Index_10
      data DE_UI2Sens02_CALID_Index_10: type=uint8
    IF_UI2Sens02_CALID_Index_11
      data DE_UI2Sens02_CALID_Index_11: type=uint8
    IF_UI2Sens02_CALID_Index_12
      data DE_UI2Sens02_CALID_Index_12: type=uint8
    IF_UI2Sens02_CALID_Index_13
      data DE_UI2Sens02_CALID_Index_13: type=uint8
    IF_UI2Sens02_CALID_Index_14
      data DE_UI2Sens02_CALID_Index_14: type=uint8
    IF_UI2Sens02_CALID_Index_15
      data DE_UI2Sens02_CALID_Index_15: type=uint8
    IF_UI2Sens02_CALID_Index_16
      data DE_UI2Sens02_CALID_Index_16: type=uint8
    IF_UI2Sens02_CVN_Byte_1
      data DE_UI2Sens02_CVN_Byte_1: type=uint8
    IF_UI2Sens02_CVN_Byte_2
      data DE_UI2Sens02_CVN_Byte_2: type=uint8
    IF_UI2Sens02_CVN_Byte_3
      data DE_UI2Sens02_CVN_Byte_3: type=uint8
    IF_UI2Sens02_CVN_Byte_4
      data DE_UI2Sens02_CVN_Byte_4: type=uint8
    IF_UI2Sens02_CVN_VLD
      data DE_UI2Sens02_CVN_VLD: type=boolean
    IF_UI2Sens02_ErrMem_State
      data DE_UI2Sens02_ErrMem_State: type=uint8
    IF_UISensorIso_01_BZ
      data DE_UISensorIso_01_BZ: type=uint8
    IF_UISensorIso_01_CRC
      data DE_UISensorIso_01_CRC: type=uint8
    IF_UISensorIso_02_BZ
      data DE_UISensorIso_02_BZ: type=uint8
    IF_UISensorIso_02_CRC
      data DE_UISensorIso_02_CRC: type=uint8
    IF_UISensorPyro_01_BZ
      data DE_UISensorPyro_01_BZ: type=uint8
    IF_UISensorPyro_01_CRC
      data DE_UISensorPyro_01_CRC: type=uint8
    IF_UISensorPyro_02_BZ
      data DE_UISensorPyro_02_BZ: type=uint8
    IF_UISensorPyro_02_CRC
      data DE_UISensorPyro_02_CRC: type=uint8
    IF_UISensorPyro_03_BZ
      data DE_UISensorPyro_03_BZ: type=uint8
    IF_UISensorPyro_03_CRC
      data DE_UISensorPyro_03_CRC: type=uint8
    IF_VDSO_Vx3d
      data DE_VDSO_Vx3d: type=uint16
    IF_VehicleProtectedEnvironment_D
      data DE_VehicleProtectedEnvironment_D: type=uint8
    IF_VIN_1
      data DE_VIN_1: type=uint8
    IF_VIN_10
      data DE_VIN_10: type=uint8
    IF_VIN_11
      data DE_VIN_11: type=uint8
    IF_VIN_12
      data DE_VIN_12: type=uint8
    IF_VIN_13
      data DE_VIN_13: type=uint8
    IF_VIN_14
      data DE_VIN_14: type=uint8
    IF_VIN_15
      data DE_VIN_15: type=uint8
    IF_VIN_16
      data DE_VIN_16: type=uint8
    IF_VIN_17
      data DE_VIN_17: type=uint8
    IF_VIN_2
      data DE_VIN_2: type=uint8
    IF_VIN_3
      data DE_VIN_3: type=uint8
    IF_VIN_4
      data DE_VIN_4: type=uint8
    IF_VIN_5
      data DE_VIN_5: type=uint8
    IF_VIN_6
      data DE_VIN_6: type=uint8
    IF_VIN_7
      data DE_VIN_7: type=uint8
    IF_VIN_8
      data DE_VIN_8: type=uint8
    IF_VIN_9
      data DE_VIN_9: type=uint8
    IF_ZM_HV_Auszeit
      data DE_ZM_HV_Auszeit: type=uint16
    IF_ZM_HV_Auszeit_HiRes
      data DE_ZM_HV_Auszeit_HiRes: type=uint16
    IF_ZM_HV_Auszeit_Status
      data DE_ZM_HV_Auszeit_Status: type=uint8
package /Interfaces/Types
  impl type DEV_Hybrid_01_Req_00_FD_Data: category=ARRAY
    element DEV_Hybrid_01_Req_00_FD_DataBase: array-size=64, array-size-semantics=FIXED-SIZE, implementation-data-type=uint8
    symbol props SymbolProps: symbol=DEV_Hybrid_01_Req_00_FD_Data
  impl type DEV_Hybrid_01_Resp_FF_FD_Data: category=ARRAY
    element DEV_Hybrid_01_Resp_FF_FD_DataBase: array-size=64, array-size-semantics=FIXED-SIZE, implementation-data-type=uint8
    symbol props SymbolProps: symbol=DEV_Hybrid_01_Resp_FF_FD_Data
package /ComponentTypes
  composition sw component type BMC_Berechnung_SOC_XIX_SoC_XIX_BMC_HV
    provide port SP_IF_Anzeige_SOC_XIX_BMC_Berechnung_SOC_XIX_SoC_XIX_BMC_HV: provided-interface=IF_Anzeige_SOC
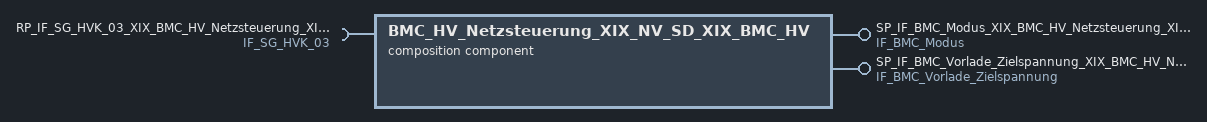
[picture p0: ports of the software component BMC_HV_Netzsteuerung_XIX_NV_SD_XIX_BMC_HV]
  composition sw component type BMC_HV_Netzsteuerung_XIX_NV_SD_XIX_BMC_HV
    provide port SP_IF_BMC_Modus_XIX_BMC_HV_Netzsteuerung_XIX_NV_SD_XIX_BMC_HV: provided-interface=IF_BMC_Modus
    provide port SP_IF_BMC_Vorlade_Zielspannung_XIX_BMC_HV_Netzsteuerung_XIX_NV_SD_XIX_BMC_HV: provided-interface=IF_BMC_Vorlade_Zielspannung
    require port RP_IF_SG_HVK_03_XIX_BMC_HV_Netzsteuerung_XIX_NV_SD_XIX_BMC_HV: required-interface=IF_SG_HVK_03
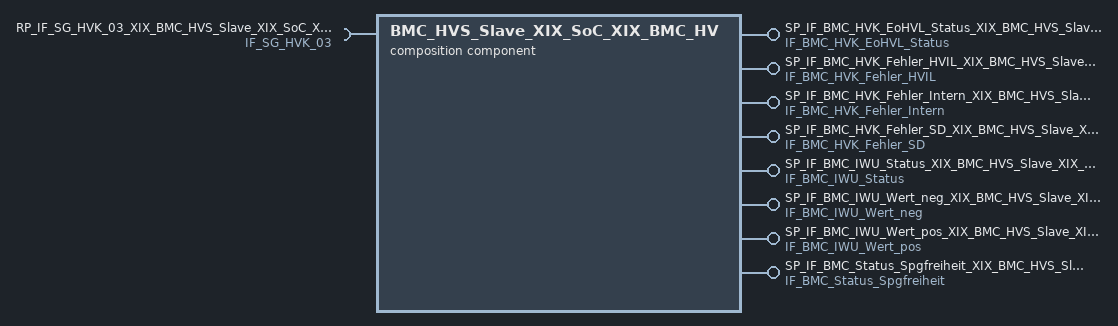
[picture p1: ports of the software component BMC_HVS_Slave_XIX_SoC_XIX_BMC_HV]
  composition sw component type BMC_HVS_Slave_XIX_SoC_XIX_BMC_HV
    8 x provide port:
      SP_IF_BMC_HVK_EoHVL_Status_XIX_BMC_HVS_Slave_XIX_SoC_XIX_BMC_HV: provided-interface=IF_BMC_HVK_EoHVL_Status
      SP_IF_BMC_HVK_Fehler_HVIL_XIX_BMC_HVS_Slave_XIX_SoC_XIX_BMC_HV: provided-interface=IF_BMC_HVK_Fehler_HVIL
      SP_IF_BMC_HVK_Fehler_Intern_XIX_BMC_HVS_Slave_XIX_SoC_XIX_BMC_HV: provided-interface=IF_BMC_HVK_Fehler_Intern
      SP_IF_BMC_HVK_Fehler_SD_XIX_BMC_HVS_Slave_XIX_SoC_XIX_BMC_HV: provided-interface=IF_BMC_HVK_Fehler_SD
      SP_IF_BMC_IWU_Status_XIX_BMC_HVS_Slave_XIX_SoC_XIX_BMC_HV: provided-interface=IF_BMC_IWU_Status
      SP_IF_BMC_IWU_Wert_neg_XIX_BMC_HVS_Slave_XIX_SoC_XIX_BMC_HV: provided-interface=IF_BMC_IWU_Wert_neg
      SP_IF_BMC_IWU_Wert_pos_XIX_BMC_HVS_Slave_XIX_SoC_XIX_BMC_HV: provided-interface=IF_BMC_IWU_Wert_pos
      SP_IF_BMC_Status_Spgfreiheit_XIX_BMC_HVS_Slave_XIX_SoC_XIX_BMC_HV: provided-interface=IF_BMC_Status_Spgfreiheit
    require port RP_IF_SG_HVK_03_XIX_BMC_HVS_Slave_XIX_SoC_XIX_BMC_HV: required-interface=IF_SG_HVK_03
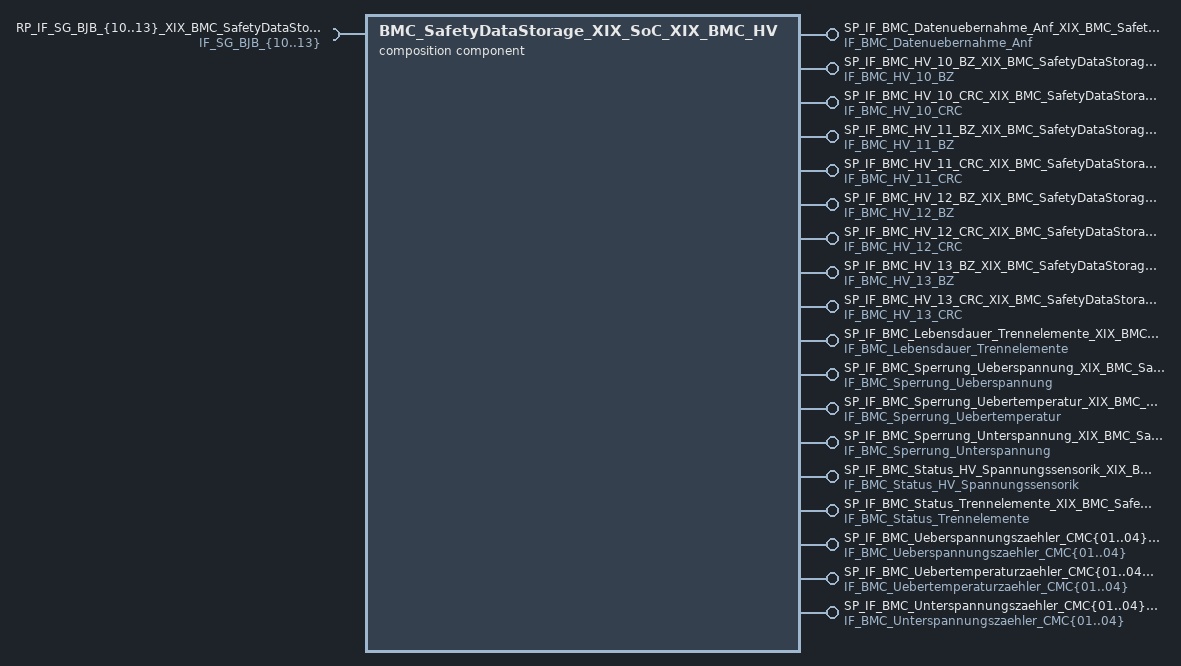
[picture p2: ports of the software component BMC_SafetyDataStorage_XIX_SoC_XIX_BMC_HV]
  composition sw component type BMC_SafetyDataStorage_XIX_SoC_XIX_BMC_HV
    27 x provide port:
      SP_IF_BMC_Datenuebernahme_Anf_XIX_BMC_SafetyDataStorage_XIX_SoC_XIX_BMC_HV: provided-interface=IF_BMC_Datenuebernahme_Anf
      SP_IF_BMC_HV_10_BZ_XIX_BMC_SafetyDataStorage_XIX_SoC_XIX_BMC_HV: provided-interface=IF_BMC_HV_10_BZ
      SP_IF_BMC_HV_10_CRC_XIX_BMC_SafetyDataStorage_XIX_SoC_XIX_BMC_HV: provided-interface=IF_BMC_HV_10_CRC
      SP_IF_BMC_HV_11_BZ_XIX_BMC_SafetyDataStorage_XIX_SoC_XIX_BMC_HV: provided-interface=IF_BMC_HV_11_BZ
      SP_IF_BMC_HV_11_CRC_XIX_BMC_SafetyDataStorage_XIX_SoC_XIX_BMC_HV: provided-interface=IF_BMC_HV_11_CRC
      SP_IF_BMC_HV_12_BZ_XIX_BMC_SafetyDataStorage_XIX_SoC_XIX_BMC_HV: provided-interface=IF_BMC_HV_12_BZ
      SP_IF_BMC_HV_12_CRC_XIX_BMC_SafetyDataStorage_XIX_SoC_XIX_BMC_HV: provided-interface=IF_BMC_HV_12_CRC
      SP_IF_BMC_HV_13_BZ_XIX_BMC_SafetyDataStorage_XIX_SoC_XIX_BMC_HV: provided-interface=IF_BMC_HV_13_BZ
      SP_IF_BMC_HV_13_CRC_XIX_BMC_SafetyDataStorage_XIX_SoC_XIX_BMC_HV: provided-interface=IF_BMC_HV_13_CRC
      SP_IF_BMC_Lebensdauer_Trennelemente_XIX_BMC_SafetyDataStorage_XIX_SoC_XIX_BMC_HV: provided-interface=IF_BMC_Lebensdauer_Trennelemente
      SP_IF_BMC_Sperrung_Ueberspannung_XIX_BMC_SafetyDataStorage_XIX_SoC_XIX_BMC_HV: provided-interface=IF_BMC_Sperrung_Ueberspannung
      SP_IF_BMC_Sperrung_Uebertemperatur_XIX_BMC_SafetyDataStorage_XIX_SoC_XIX_BMC_HV: provided-interface=IF_BMC_Sperrung_Uebertemperatur
      SP_IF_BMC_Sperrung_Unterspannung_XIX_BMC_SafetyDataStorage_XIX_SoC_XIX_BMC_HV: provided-interface=IF_BMC_Sperrung_Unterspannung
      SP_IF_BMC_Status_HV_Spannungssensorik_XIX_BMC_SafetyDataStorage_XIX_SoC_XIX_BMC_HV: provided-interface=IF_BMC_Status_HV_Spannungssensorik
      SP_IF_BMC_Status_Trennelemente_XIX_BMC_SafetyDataStorage_XIX_SoC_XIX_BMC_HV: provided-interface=IF_BMC_Status_Trennelemente
      SP_IF_BMC_Ueberspannungszaehler_CMC{01..04}_XIX_BMC_SafetyDataStorage_XIX_SoC_XIX_BMC_HV: provided-interface=IF_BMC_Ueberspannungszaehler_CMC{01..04}
      SP_IF_BMC_Uebertemperaturzaehler_CMC{01..04}_XIX_BMC_SafetyDataStorage_XIX_SoC_XIX_BMC_HV: provided-interface=IF_BMC_Uebertemperaturzaehler_CMC{01..04}
      SP_IF_BMC_Unterspannungszaehler_CMC{01..04}_XIX_BMC_SafetyDataStorage_XIX_SoC_XIX_BMC_HV: provided-interface=IF_BMC_Unterspannungszaehler_CMC{01..04}
    4 x require port:
      RP_IF_SG_BJB_{10..13}_XIX_BMC_SafetyDataStorage_XIX_SoC_XIX_BMC_HV: required-interface=IF_SG_BJB_{10..13}
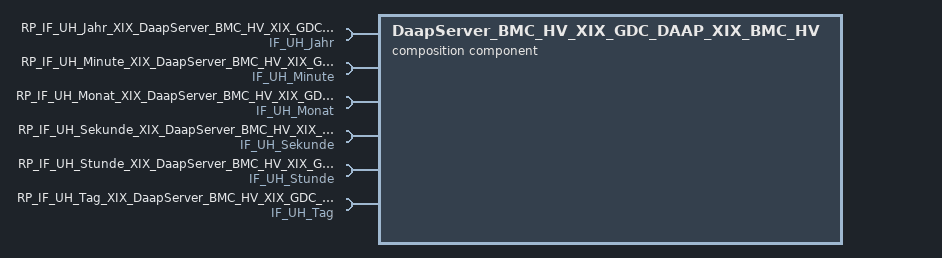
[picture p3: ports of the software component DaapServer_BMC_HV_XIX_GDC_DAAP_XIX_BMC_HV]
  composition sw component type DaapServer_BMC_HV_XIX_GDC_DAAP_XIX_BMC_HV
    6 x require port:
      RP_IF_UH_Jahr_XIX_DaapServer_BMC_HV_XIX_GDC_DAAP_XIX_BMC_HV: required-interface=IF_UH_Jahr
      RP_IF_UH_Minute_XIX_DaapServer_BMC_HV_XIX_GDC_DAAP_XIX_BMC_HV: required-interface=IF_UH_Minute
      RP_IF_UH_Monat_XIX_DaapServer_BMC_HV_XIX_GDC_DAAP_XIX_BMC_HV: required-interface=IF_UH_Monat
      RP_IF_UH_Sekunde_XIX_DaapServer_BMC_HV_XIX_GDC_DAAP_XIX_BMC_HV: required-interface=IF_UH_Sekunde
      RP_IF_UH_Stunde_XIX_DaapServer_BMC_HV_XIX_GDC_DAAP_XIX_BMC_HV: required-interface=IF_UH_Stunde
      RP_IF_UH_Tag_XIX_DaapServer_BMC_HV_XIX_GDC_DAAP_XIX_BMC_HV: required-interface=IF_UH_Tag
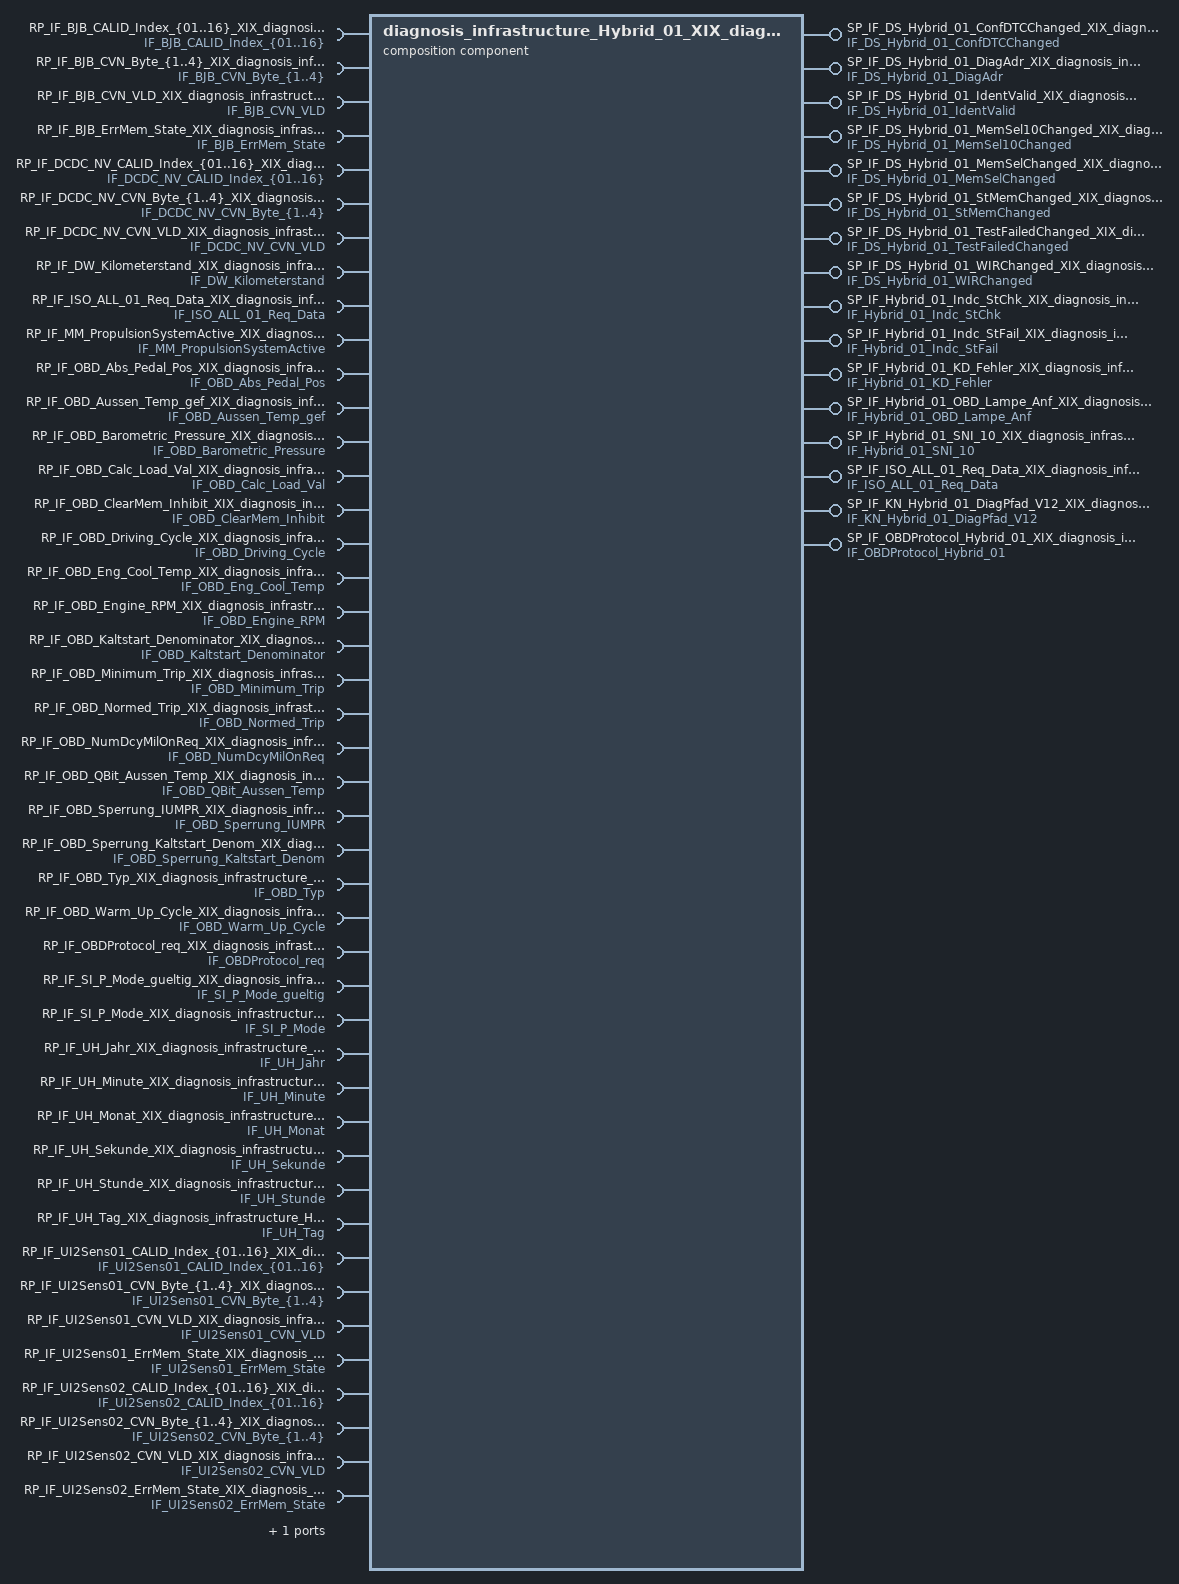
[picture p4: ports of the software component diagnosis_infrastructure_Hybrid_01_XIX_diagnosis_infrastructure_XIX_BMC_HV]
  composition sw component type diagnosis_infrastructure_Hybrid_01_XIX_diagnosis_infrastructure_XIX_BMC_HV
    16 x provide port:
      SP_IF_DS_Hybrid_01_ConfDTCChanged_XIX_diagnosis_infrastructure_Hybrid_01_XIX_diagnosis_infrastructure_XIX_BMC_HV: provided-interface=IF_DS_Hybrid_01_ConfDTCChanged
      SP_IF_DS_Hybrid_01_DiagAdr_XIX_diagnosis_infrastructure_Hybrid_01_XIX_diagnosis_infrastructure_XIX_BMC_HV: provided-interface=IF_DS_Hybrid_01_DiagAdr
      SP_IF_DS_Hybrid_01_IdentValid_XIX_diagnosis_infrastructure_Hybrid_01_XIX_diagnosis_infrastructure_XIX_BMC_HV: provided-interface=IF_DS_Hybrid_01_IdentValid
      SP_IF_DS_Hybrid_01_MemSel10Changed_XIX_diagnosis_infrastructure_Hybrid_01_XIX_diagnosis_infrastructure_XIX_BMC_HV: provided-interface=IF_DS_Hybrid_01_MemSel10Changed
      SP_IF_DS_Hybrid_01_MemSelChanged_XIX_diagnosis_infrastructure_Hybrid_01_XIX_diagnosis_infrastructure_XIX_BMC_HV: provided-interface=IF_DS_Hybrid_01_MemSelChanged
      SP_IF_DS_Hybrid_01_StMemChanged_XIX_diagnosis_infrastructure_Hybrid_01_XIX_diagnosis_infrastructure_XIX_BMC_HV: provided-interface=IF_DS_Hybrid_01_StMemChanged
      SP_IF_DS_Hybrid_01_TestFailedChanged_XIX_diagnosis_infrastructure_Hybrid_01_XIX_diagnosis_infrastructure_XIX_BMC_HV: provided-interface=IF_DS_Hybrid_01_TestFailedChanged
      SP_IF_DS_Hybrid_01_WIRChanged_XIX_diagnosis_infrastructure_Hybrid_01_XIX_diagnosis_infrastructure_XIX_BMC_HV: provided-interface=IF_DS_Hybrid_01_WIRChanged
      SP_IF_Hybrid_01_Indc_StChk_XIX_diagnosis_infrastructure_Hybrid_01_XIX_diagnosis_infrastructure_XIX_BMC_HV: provided-interface=IF_Hybrid_01_Indc_StChk
      SP_IF_Hybrid_01_Indc_StFail_XIX_diagnosis_infrastructure_Hybrid_01_XIX_diagnosis_infrastructure_XIX_BMC_HV: provided-interface=IF_Hybrid_01_Indc_StFail
      SP_IF_Hybrid_01_KD_Fehler_XIX_diagnosis_infrastructure_Hybrid_01_XIX_diagnosis_infrastructure_XIX_BMC_HV: provided-interface=IF_Hybrid_01_KD_Fehler
      SP_IF_Hybrid_01_OBD_Lampe_Anf_XIX_diagnosis_infrastructure_Hybrid_01_XIX_diagnosis_infrastructure_XIX_BMC_HV: provided-interface=IF_Hybrid_01_OBD_Lampe_Anf
      SP_IF_Hybrid_01_SNI_10_XIX_diagnosis_infrastructure_Hybrid_01_XIX_diagnosis_infrastructure_XIX_BMC_HV: provided-interface=IF_Hybrid_01_SNI_10
      SP_IF_ISO_ALL_01_Req_Data_XIX_diagnosis_infrastructure_Hybrid_01_XIX_diagnosis_infrastructure_XIX_BMC_HV: provided-interface=IF_ISO_ALL_01_Req_Data
      SP_IF_KN_Hybrid_01_DiagPfad_V12_XIX_diagnosis_infrastructure_Hybrid_01_XIX_diagnosis_infrastructure_XIX_BMC_HV: provided-interface=IF_KN_Hybrid_01_DiagPfad_V12
      SP_IF_OBDProtocol_Hybrid_01_XIX_diagnosis_infrastructure_Hybrid_01_XIX_diagnosis_infrastructure_XIX_BMC_HV: provided-interface=IF_OBDProtocol_Hybrid_01
    117 x require port:
      RP_IF_BJB_CALID_Index_{01..16}_XIX_diagnosis_infrastructure_Hybrid_01_XIX_diagnosis_infrastructure_XIX_BMC_HV: required-interface=IF_BJB_CALID_Index_{01..16}
      RP_IF_BJB_CVN_Byte_{1..4}_XIX_diagnosis_infrastructure_Hybrid_01_XIX_diagnosis_infrastructure_XIX_BMC_HV: required-interface=IF_BJB_CVN_Byte_{1..4}
      RP_IF_BJB_CVN_VLD_XIX_diagnosis_infrastructure_Hybrid_01_XIX_diagnosis_infrastructure_XIX_BMC_HV: required-interface=IF_BJB_CVN_VLD
      RP_IF_BJB_ErrMem_State_XIX_diagnosis_infrastructure_Hybrid_01_XIX_diagnosis_infrastructure_XIX_BMC_HV: required-interface=IF_BJB_ErrMem_State
      RP_IF_DCDC_NV_CALID_Index_{01..16}_XIX_diagnosis_infrastructure_Hybrid_01_XIX_diagnosis_infrastructure_XIX_BMC_HV: required-interface=IF_DCDC_NV_CALID_Index_{01..16}
      RP_IF_DCDC_NV_CVN_Byte_{1..4}_XIX_diagnosis_infrastructure_Hybrid_01_XIX_diagnosis_infrastructure_XIX_BMC_HV: required-interface=IF_DCDC_NV_CVN_Byte_{1..4}
      RP_IF_DCDC_NV_CVN_VLD_XIX_diagnosis_infrastructure_Hybrid_01_XIX_diagnosis_infrastructure_XIX_BMC_HV: required-interface=IF_DCDC_NV_CVN_VLD
      RP_IF_DW_Kilometerstand_XIX_diagnosis_infrastructure_Hybrid_01_XIX_diagnosis_infrastructure_XIX_BMC_HV: required-interface=IF_DW_Kilometerstand
      RP_IF_ISO_ALL_01_Req_Data_XIX_diagnosis_infrastructure_Hybrid_01_XIX_diagnosis_infrastructure_XIX_BMC_HV: required-interface=IF_ISO_ALL_01_Req_Data
      RP_IF_MM_PropulsionSystemActive_XIX_diagnosis_infrastructure_Hybrid_01_XIX_diagnosis_infrastructure_XIX_BMC_HV: required-interface=IF_MM_PropulsionSystemActive
      RP_IF_OBD_Abs_Pedal_Pos_XIX_diagnosis_infrastructure_Hybrid_01_XIX_diagnosis_infrastructure_XIX_BMC_HV: required-interface=IF_OBD_Abs_Pedal_Pos
      RP_IF_OBD_Aussen_Temp_gef_XIX_diagnosis_infrastructure_Hybrid_01_XIX_diagnosis_infrastructure_XIX_BMC_HV: required-interface=IF_OBD_Aussen_Temp_gef
      RP_IF_OBD_Barometric_Pressure_XIX_diagnosis_infrastructure_Hybrid_01_XIX_diagnosis_infrastructure_XIX_BMC_HV: required-interface=IF_OBD_Barometric_Pressure
      RP_IF_OBD_Calc_Load_Val_XIX_diagnosis_infrastructure_Hybrid_01_XIX_diagnosis_infrastructure_XIX_BMC_HV: required-interface=IF_OBD_Calc_Load_Val
      RP_IF_OBD_ClearMem_Inhibit_XIX_diagnosis_infrastructure_Hybrid_01_XIX_diagnosis_infrastructure_XIX_BMC_HV: required-interface=IF_OBD_ClearMem_Inhibit
      RP_IF_OBD_Driving_Cycle_XIX_diagnosis_infrastructure_Hybrid_01_XIX_diagnosis_infrastructure_XIX_BMC_HV: required-interface=IF_OBD_Driving_Cycle
      RP_IF_OBD_Eng_Cool_Temp_XIX_diagnosis_infrastructure_Hybrid_01_XIX_diagnosis_infrastructure_XIX_BMC_HV: required-interface=IF_OBD_Eng_Cool_Temp
      RP_IF_OBD_Engine_RPM_XIX_diagnosis_infrastructure_Hybrid_01_XIX_diagnosis_infrastructure_XIX_BMC_HV: required-interface=IF_OBD_Engine_RPM
      RP_IF_OBD_Kaltstart_Denominator_XIX_diagnosis_infrastructure_Hybrid_01_XIX_diagnosis_infrastructure_XIX_BMC_HV: required-interface=IF_OBD_Kaltstart_Denominator
      RP_IF_OBD_Minimum_Trip_XIX_diagnosis_infrastructure_Hybrid_01_XIX_diagnosis_infrastructure_XIX_BMC_HV: required-interface=IF_OBD_Minimum_Trip
      RP_IF_OBD_Normed_Trip_XIX_diagnosis_infrastructure_Hybrid_01_XIX_diagnosis_infrastructure_XIX_BMC_HV: required-interface=IF_OBD_Normed_Trip
      RP_IF_OBD_NumDcyMilOnReq_XIX_diagnosis_infrastructure_Hybrid_01_XIX_diagnosis_infrastructure_XIX_BMC_HV: required-interface=IF_OBD_NumDcyMilOnReq
      RP_IF_OBD_QBit_Aussen_Temp_XIX_diagnosis_infrastructure_Hybrid_01_XIX_diagnosis_infrastructure_XIX_BMC_HV: required-interface=IF_OBD_QBit_Aussen_Temp
      RP_IF_OBD_Sperrung_IUMPR_XIX_diagnosis_infrastructure_Hybrid_01_XIX_diagnosis_infrastructure_XIX_BMC_HV: required-interface=IF_OBD_Sperrung_IUMPR
      RP_IF_OBD_Sperrung_Kaltstart_Denom_XIX_diagnosis_infrastructure_Hybrid_01_XIX_diagnosis_infrastructure_XIX_BMC_HV: required-interface=IF_OBD_Sperrung_Kaltstart_Denom
      RP_IF_OBD_Typ_XIX_diagnosis_infrastructure_Hybrid_01_XIX_diagnosis_infrastructure_XIX_BMC_HV: required-interface=IF_OBD_Typ
      RP_IF_OBD_Warm_Up_Cycle_XIX_diagnosis_infrastructure_Hybrid_01_XIX_diagnosis_infrastructure_XIX_BMC_HV: required-interface=IF_OBD_Warm_Up_Cycle
      RP_IF_OBDProtocol_req_XIX_diagnosis_infrastructure_Hybrid_01_XIX_diagnosis_infrastructure_XIX_BMC_HV: required-interface=IF_OBDProtocol_req
      RP_IF_SI_P_Mode_gueltig_XIX_diagnosis_infrastructure_Hybrid_01_XIX_diagnosis_infrastructure_XIX_BMC_HV: required-interface=IF_SI_P_Mode_gueltig
      RP_IF_SI_P_Mode_XIX_diagnosis_infrastructure_Hybrid_01_XIX_diagnosis_infrastructure_XIX_BMC_HV: required-interface=IF_SI_P_Mode
      RP_IF_UH_Jahr_XIX_diagnosis_infrastructure_Hybrid_01_XIX_diagnosis_infrastructure_XIX_BMC_HV: required-interface=IF_UH_Jahr
      RP_IF_UH_Minute_XIX_diagnosis_infrastructure_Hybrid_01_XIX_diagnosis_infrastructure_XIX_BMC_HV: required-interface=IF_UH_Minute
      RP_IF_UH_Monat_XIX_diagnosis_infrastructure_Hybrid_01_XIX_diagnosis_infrastructure_XIX_BMC_HV: required-interface=IF_UH_Monat
      RP_IF_UH_Sekunde_XIX_diagnosis_infrastructure_Hybrid_01_XIX_diagnosis_infrastructure_XIX_BMC_HV: required-interface=IF_UH_Sekunde
      RP_IF_UH_Stunde_XIX_diagnosis_infrastructure_Hybrid_01_XIX_diagnosis_infrastructure_XIX_BMC_HV: required-interface=IF_UH_Stunde
      RP_IF_UH_Tag_XIX_diagnosis_infrastructure_Hybrid_01_XIX_diagnosis_infrastructure_XIX_BMC_HV: required-interface=IF_UH_Tag
      RP_IF_UI2Sens01_CALID_Index_{01..16}_XIX_diagnosis_infrastructure_Hybrid_01_XIX_diagnosis_infrastructure_XIX_BMC_HV: required-interface=IF_UI2Sens01_CALID_Index_{01..16}
      RP_IF_UI2Sens01_CVN_Byte_{1..4}_XIX_diagnosis_infrastructure_Hybrid_01_XIX_diagnosis_infrastructure_XIX_BMC_HV: required-interface=IF_UI2Sens01_CVN_Byte_{1..4}
      RP_IF_UI2Sens01_CVN_VLD_XIX_diagnosis_infrastructure_Hybrid_01_XIX_diagnosis_infrastructure_XIX_BMC_HV: required-interface=IF_UI2Sens01_CVN_VLD
      RP_IF_UI2Sens01_ErrMem_State_XIX_diagnosis_infrastructure_Hybrid_01_XIX_diagnosis_infrastructure_XIX_BMC_HV: required-interface=IF_UI2Sens01_ErrMem_State
      RP_IF_UI2Sens02_CALID_Index_{01..16}_XIX_diagnosis_infrastructure_Hybrid_01_XIX_diagnosis_infrastructure_XIX_BMC_HV: required-interface=IF_UI2Sens02_CALID_Index_{01..16}
      RP_IF_UI2Sens02_CVN_Byte_{1..4}_XIX_diagnosis_infrastructure_Hybrid_01_XIX_diagnosis_infrastructure_XIX_BMC_HV: required-interface=IF_UI2Sens02_CVN_Byte_{1..4}
      RP_IF_UI2Sens02_CVN_VLD_XIX_diagnosis_infrastructure_Hybrid_01_XIX_diagnosis_infrastructure_XIX_BMC_HV: required-interface=IF_UI2Sens02_CVN_VLD
      RP_IF_UI2Sens02_ErrMem_State_XIX_diagnosis_infrastructure_Hybrid_01_XIX_diagnosis_infrastructure_XIX_BMC_HV: required-interface=IF_UI2Sens02_ErrMem_State
      RP_IF_VDSO_Vx3d_XIX_diagnosis_infrastructure_Hybrid_01_XIX_diagnosis_infrastructure_XIX_BMC_HV: required-interface=IF_VDSO_Vx3d
